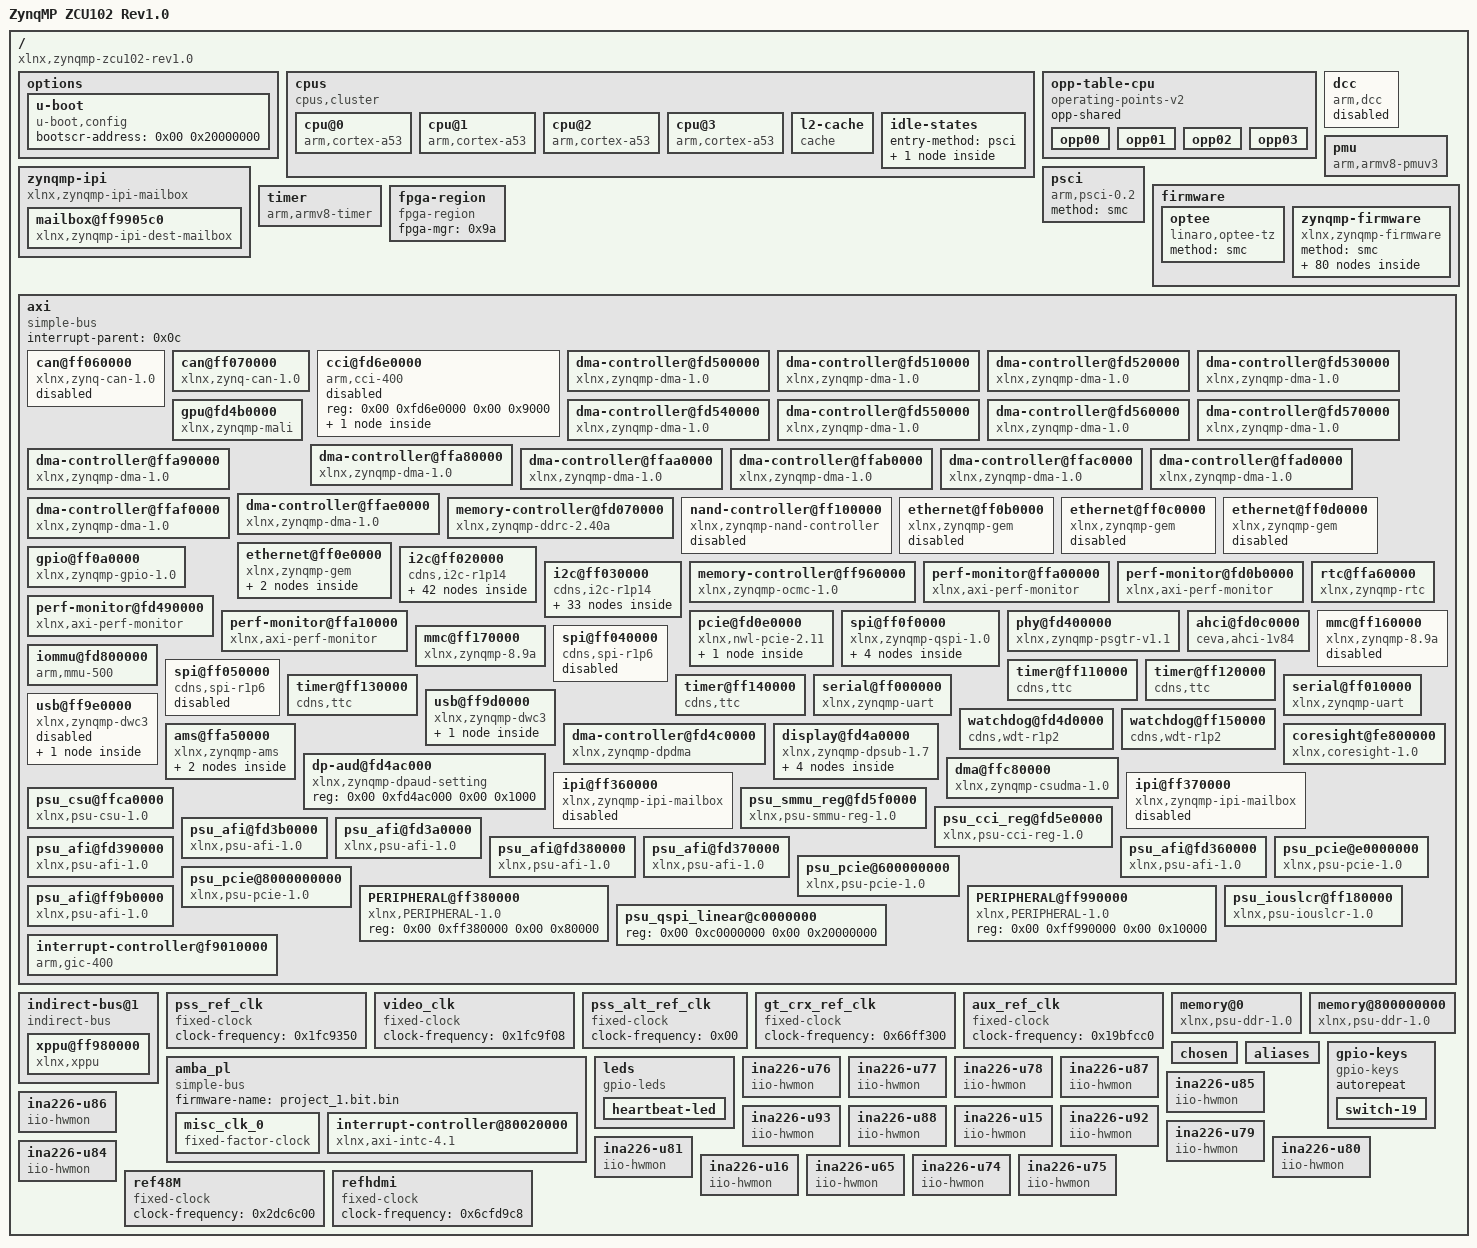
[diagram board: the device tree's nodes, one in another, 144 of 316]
/dts-v1/;

/ {
	compatible = "xlnx,zynqmp-zcu102-rev1.0\0xlnx,zynqmp-zcu102\0xlnx,zynqmp";
	#address-cells = <0x02>;
	#size-cells = <0x02>;
	model = "ZynqMP ZCU102 Rev1.0";
	board = "zcu102";
	device_id = "xczu9eg";
	slrcount = <0x01>;
	family = "ZynqMP";

	options {

		u-boot {
			compatible = "u-boot,config";
			bootscr-address = <0x00 0x20000000>;
		};
	};

	cpus {
		#address-cells = <0x01>;
		#size-cells = <0x00>;
		compatible = "cpus,cluster";
		#ranges-address-cells = <0x02>;
		#ranges-size-cells = <0x02>;
		phandle = <0xc4>;

		cpu@0 {
			compatible = "arm,cortex-a53";
			device_type = "cpu";
			enable-method = "psci";
			operating-points-v2 = <0x78>;
			reg = <0x00>;
			cpu-idle-states = <0x79>;
			next-level-cache = <0x7a>;
			clocks = <0x7b 0x0a>;
			xlnx,psu-ep = <0x01>;
			xlnx,pss-video-ref-clk-freq = <0x1fc9f08>;
			xlnx,ip-name = "psu_cortexa53";
			xlnx,cpu-1x-clk-freq-hz = <0x00>;
			xlnx,psu-silicon-version = <0x03>;
			cpu-frequency = <0x4784b7bf>;
			xlnx,cpu-clk-freq-hz = <0x4784b7bf>;
			xlnx,pss-gt-ref-clk-freq = <0x1fc9f08>;
			xlnx,pss-ref-clk-freq = <0x1fc9350>;
			bus-handle = <0x01>;
			xlnx,pss-aux-ref-clk-freq = <0x1fc9f08>;
			xlnx,psu-device = "PS8a";
			xlnx,timestamp-clk-freq = <0x5f5b9f5>;
			stamp-frequency = <0x5f5b9f5>;
			xlnx,pss-alt-ref-clk-freq = <0x1fc9f08>;
			phandle = <0x90>;
		};

		cpu@1 {
			compatible = "arm,cortex-a53";
			device_type = "cpu";
			enable-method = "psci";
			reg = <0x01>;
			operating-points-v2 = <0x78>;
			cpu-idle-states = <0x79>;
			next-level-cache = <0x7a>;
			xlnx,psu-ep = <0x01>;
			xlnx,ip-name = "psu_cortexa53";
			xlnx,cpu-1x-clk-freq-hz = <0x00>;
			cpu-frequency = <0x4784b7bf>;
			xlnx,cpu-clk-freq-hz = <0x4784b7bf>;
			xlnx,psu-silicon-version = <0x03>;
			xlnx,pss-ref-clk-freq = <0x1fc9350>;
			bus-handle = <0x01>;
			xlnx,psu-device = "PS8a";
			stamp-frequency = <0x5f5b9f5>;
			xlnx,timestamp-clk-freq = <0x5f5b9f5>;
			phandle = <0x91>;
		};

		cpu@2 {
			compatible = "arm,cortex-a53";
			device_type = "cpu";
			enable-method = "psci";
			reg = <0x02>;
			operating-points-v2 = <0x78>;
			cpu-idle-states = <0x79>;
			next-level-cache = <0x7a>;
			xlnx,psu-ep = <0x01>;
			xlnx,ip-name = "psu_cortexa53";
			xlnx,cpu-1x-clk-freq-hz = <0x00>;
			cpu-frequency = <0x4784b7bf>;
			xlnx,cpu-clk-freq-hz = <0x4784b7bf>;
			xlnx,psu-silicon-version = <0x03>;
			xlnx,pss-ref-clk-freq = <0x1fc9350>;
			bus-handle = <0x01>;
			xlnx,psu-device = "PS8a";
			stamp-frequency = <0x5f5b9f5>;
			xlnx,timestamp-clk-freq = <0x5f5b9f5>;
			phandle = <0x92>;
		};

		cpu@3 {
			compatible = "arm,cortex-a53";
			device_type = "cpu";
			enable-method = "psci";
			reg = <0x03>;
			operating-points-v2 = <0x78>;
			cpu-idle-states = <0x79>;
			next-level-cache = <0x7a>;
			xlnx,psu-ep = <0x01>;
			xlnx,ip-name = "psu_cortexa53";
			xlnx,cpu-1x-clk-freq-hz = <0x00>;
			cpu-frequency = <0x4784b7bf>;
			xlnx,cpu-clk-freq-hz = <0x4784b7bf>;
			xlnx,psu-silicon-version = <0x03>;
			xlnx,pss-ref-clk-freq = <0x1fc9350>;
			bus-handle = <0x01>;
			xlnx,psu-device = "PS8a";
			stamp-frequency = <0x5f5b9f5>;
			xlnx,timestamp-clk-freq = <0x5f5b9f5>;
			phandle = <0x93>;
		};

		l2-cache {
			compatible = "cache";
			cache-level = <0x02>;
			cache-unified;
			phandle = <0x7a>;
		};

		idle-states {
			entry-method = "psci";

			cpu-sleep-0 {
				compatible = "arm,idle-state";
				arm,psci-suspend-param = <0x40000000>;
				local-timer-stop;
				entry-latency-us = <0x12c>;
				exit-latency-us = <0x258>;
				min-residency-us = <0x2710>;
				phandle = <0x79>;
			};
		};
	};

	opp-table-cpu {
		compatible = "operating-points-v2";
		opp-shared;
		phandle = <0x78>;

		opp00 {
			opp-hz = <0x00 0x47868bf4>;
			opp-microvolt = <0xf4240>;
			clock-latency-ns = <0x7a120>;
		};

		opp01 {
			opp-hz = <0x00 0x23c345fa>;
			opp-microvolt = <0xf4240>;
			clock-latency-ns = <0x7a120>;
		};

		opp02 {
			opp-hz = <0x00 0x17d783fc>;
			opp-microvolt = <0xf4240>;
			clock-latency-ns = <0x7a120>;
		};

		opp03 {
			opp-hz = <0x00 0x11e1a2fd>;
			opp-microvolt = <0xf4240>;
			clock-latency-ns = <0x7a120>;
		};
	};

	zynqmp-ipi {
		bootph-all;
		compatible = "xlnx,zynqmp-ipi-mailbox";
		interrupt-parent = <0x0c>;
		interrupts = <0x00 0x23 0x04>;
		xlnx,ipi-id = <0x00>;
		#address-cells = <0x02>;
		#size-cells = <0x02>;
		ranges;
		phandle = <0xcb>;

		mailbox@ff9905c0 {
			bootph-all;
			compatible = "xlnx,zynqmp-ipi-dest-mailbox";
			reg = <0x00 0xff9905c0 0x00 0x20 0x00 0xff9905e0 0x00 0x20 0x00 0xff990e80 0x00 0x20 0x00 0xff990ea0 0x00 0x20>;
			reg-names = "local_request_region\0local_response_region\0remote_request_region\0remote_response_region";
			#mbox-cells = <0x01>;
			xlnx,ipi-id = <0x04>;
			phandle = <0x94>;
		};
	};

	dcc {
		compatible = "arm,dcc";
		status = "disabled";
		bootph-all;
		phandle = <0xcc>;
	};

	pmu {
		compatible = "arm,armv8-pmuv3";
		interrupt-parent = <0x0c>;
		interrupts = <0x00 0x8f 0x04 0x00 0x90 0x04 0x00 0x91 0x04 0x00 0x92 0x04>;
		interrupt-affinity = <0x90 0x91 0x92 0x93>;
	};

	psci {
		compatible = "arm,psci-0.2";
		method = "smc";
	};

	firmware {

		optee {
			compatible = "linaro,optee-tz";
			method = "smc";
			phandle = <0xcd>;
		};

		zynqmp-firmware {
			compatible = "xlnx,zynqmp-firmware";
			#power-domain-cells = <0x01>;
			method = "smc";
			bootph-all;
			phandle = <0x84>;

			power-management {
				bootph-all;
				compatible = "xlnx,zynqmp-power";
				interrupt-parent = <0x0c>;
				interrupts = <0x00 0x23 0x04>;
				mboxes = <0x94 0x00 0x94 0x01>;
				mbox-names = "tx\0rx";
				phandle = <0xce>;
			};

			soc-nvmem {
				compatible = "xlnx,zynqmp-nvmem-fw";

				nvmem-layout {
					compatible = "fixed-layout";
					#address-cells = <0x01>;
					#size-cells = <0x01>;

					soc-revision@0 {
						reg = <0x00 0x04>;
						phandle = <0xcf>;
					};

					efuse-dna@c {
						reg = <0x0c 0x0c>;
						phandle = <0xd0>;
					};

					efuse-usr0@20 {
						reg = <0x20 0x04>;
						phandle = <0xd1>;
					};

					efuse-usr1@24 {
						reg = <0x24 0x04>;
						phandle = <0xd2>;
					};

					efuse-usr2@28 {
						reg = <0x28 0x04>;
						phandle = <0xd3>;
					};

					efuse-usr3@2c {
						reg = <0x2c 0x04>;
						phandle = <0xd4>;
					};

					efuse-usr4@30 {
						reg = <0x30 0x04>;
						phandle = <0xd5>;
					};

					efuse-usr5@34 {
						reg = <0x34 0x04>;
						phandle = <0xd6>;
					};

					efuse-usr6@38 {
						reg = <0x38 0x04>;
						phandle = <0xd7>;
					};

					efuse-usr7@3c {
						reg = <0x3c 0x04>;
						phandle = <0xd8>;
					};

					efuse-miscusr@40 {
						reg = <0x40 0x04>;
						phandle = <0xd9>;
					};

					efuse-chash@50 {
						reg = <0x50 0x04>;
						phandle = <0xda>;
					};

					efuse-pufmisc@54 {
						reg = <0x54 0x04>;
						phandle = <0xdb>;
					};

					efuse-sec@58 {
						reg = <0x58 0x04>;
						phandle = <0xdc>;
					};

					efuse-spkid@5c {
						reg = <0x5c 0x04>;
						phandle = <0xdd>;
					};

					efuse-aeskey@60 {
						reg = <0x60 0x20>;
						phandle = <0xde>;
					};

					efuse-ppk0hash@a0 {
						reg = <0xa0 0x30>;
						phandle = <0xdf>;
					};

					efuse-ppk1hash@d0 {
						reg = <0xd0 0x30>;
						phandle = <0xe0>;
					};

					efuse-pufuser@100 {
						reg = <0x100 0x7f>;
						phandle = <0xe1>;
					};
				};
			};

			pcap {
				compatible = "xlnx,zynqmp-pcap-fpga";
				phandle = <0x9a>;
			};

			reset-controller {
				compatible = "xlnx,zynqmp-reset";
				#reset-cells = <0x01>;
				status = "okay";
				phandle = <0x03>;
			};

			pinctrl {
				compatible = "xlnx,zynqmp-pinctrl";
				status = "okay";
				phandle = <0x04>;

				i2c0-default {
					phandle = <0xa0>;

					mux {
						groups = "i2c0_3_grp";
						function = "i2c0";
					};

					conf {
						groups = "i2c0_3_grp";
						bias-pull-up;
						slew-rate = <0x01>;
						power-source = <0x01>;
					};
				};

				i2c0-gpio-grp {
					phandle = <0xa1>;

					mux {
						groups = "gpio0_14_grp\0gpio0_15_grp";
						function = "gpio0";
					};

					conf {
						groups = "gpio0_14_grp\0gpio0_15_grp";
						slew-rate = <0x01>;
						power-source = <0x01>;
					};
				};

				i2c1-default {
					phandle = <0xa2>;

					mux {
						groups = "i2c1_4_grp";
						function = "i2c1";
					};

					conf {
						groups = "i2c1_4_grp";
						bias-pull-up;
						slew-rate = <0x01>;
						power-source = <0x01>;
					};
				};

				i2c1-gpio-grp {
					phandle = <0xa3>;

					mux {
						groups = "gpio0_16_grp\0gpio0_17_grp";
						function = "gpio0";
					};

					conf {
						groups = "gpio0_16_grp\0gpio0_17_grp";
						slew-rate = <0x01>;
						power-source = <0x01>;
					};
				};

				uart0-default {
					phandle = <0xa9>;

					mux {
						groups = "uart0_4_grp";
						function = "uart0";
					};

					conf {
						groups = "uart0_4_grp";
						slew-rate = <0x01>;
						power-source = <0x01>;
					};

					conf-rx {
						pins = "MIO18";
						bias-high-impedance;
					};

					conf-tx {
						pins = "MIO19";
						bias-disable;
					};
				};

				uart1-default {
					phandle = <0xaa>;

					mux {
						groups = "uart1_5_grp";
						function = "uart1";
					};

					conf {
						groups = "uart1_5_grp";
						slew-rate = <0x01>;
						power-source = <0x01>;
					};

					conf-rx {
						pins = "MIO21";
						bias-high-impedance;
					};

					conf-tx {
						pins = "MIO20";
						bias-disable;
					};
				};

				usb0-default {
					phandle = <0xac>;

					mux {
						groups = "usb0_0_grp";
						function = "usb0";
					};

					conf {
						groups = "usb0_0_grp";
						power-source = <0x01>;
					};

					conf-rx {
						pins = "MIO52\0MIO53\0MIO55";
						bias-high-impedance;
						drive-strength = <0x0c>;
						slew-rate = <0x00>;
					};

					conf-tx {
						pins = "MIO54\0MIO56\0MIO57\0MIO58\0MIO59\0MIO60\0MIO61\0MIO62\0MIO63";
						bias-disable;
						drive-strength = <0x04>;
						slew-rate = <0x01>;
					};
				};

				gem3-default {
					phandle = <0x9d>;

					mux {
						function = "ethernet3";
						groups = "ethernet3_0_grp";
					};

					conf {
						groups = "ethernet3_0_grp";
						slew-rate = <0x01>;
						power-source = <0x01>;
					};

					conf-rx {
						pins = "MIO70\0MIO71\0MIO72\0MIO73\0MIO74\0MIO75";
						bias-high-impedance;
						low-power-disable;
					};

					conf-tx {
						pins = "MIO64\0MIO65\0MIO66\0MIO67\0MIO68\0MIO69";
						bias-disable;
						low-power-enable;
					};

					mux-mdio {
						function = "mdio3";
						groups = "mdio3_0_grp";
					};

					conf-mdio {
						groups = "mdio3_0_grp";
						slew-rate = <0x01>;
						power-source = <0x01>;
						bias-disable;
					};
				};

				can1-default {
					phandle = <0x9b>;

					mux {
						function = "can1";
						groups = "can1_6_grp";
					};

					conf {
						groups = "can1_6_grp";
						slew-rate = <0x01>;
						power-source = <0x01>;
					};

					conf-rx {
						pins = "MIO25";
						bias-high-impedance;
					};

					conf-tx {
						pins = "MIO24";
						bias-disable;
					};
				};

				sdhci1-default {
					phandle = <0xa8>;

					mux {
						groups = "sdio1_0_grp";
						function = "sdio1";
					};

					conf {
						groups = "sdio1_0_grp";
						slew-rate = <0x01>;
						power-source = <0x01>;
						bias-disable;
					};

					mux-cd {
						groups = "sdio1_cd_0_grp";
						function = "sdio1_cd";
					};

					conf-cd {
						groups = "sdio1_cd_0_grp";
						bias-high-impedance;
						bias-pull-up;
						slew-rate = <0x01>;
						power-source = <0x01>;
					};

					mux-wp {
						groups = "sdio1_wp_0_grp";
						function = "sdio1_wp";
					};

					conf-wp {
						groups = "sdio1_wp_0_grp";
						bias-high-impedance;
						bias-pull-up;
						slew-rate = <0x01>;
						power-source = <0x01>;
					};
				};

				gpio-default {
					phandle = <0x9f>;

					mux-sw {
						function = "gpio0";
						groups = "gpio0_22_grp\0gpio0_23_grp";
					};

					conf-sw {
						groups = "gpio0_22_grp\0gpio0_23_grp";
						slew-rate = <0x01>;
						power-source = <0x01>;
					};

					mux-msp {
						function = "gpio0";
						groups = "gpio0_13_grp\0gpio0_38_grp";
					};

					conf-msp {
						groups = "gpio0_13_grp\0gpio0_38_grp";
						slew-rate = <0x01>;
						power-source = <0x01>;
					};

					conf-pull-up {
						pins = "MIO22\0MIO23";
						bias-pull-up;
					};

					conf-pull-none {
						pins = "MIO13\0MIO38";
						bias-disable;
					};
				};
			};

			gpio {
				compatible = "xlnx,zynqmp-gpio-modepin";
				gpio-controller;
				#gpio-cells = <0x02>;
				phandle = <0xab>;
			};

			clock-controller {
				bootph-all;
				#clock-cells = <0x01>;
				compatible = "xlnx,zynqmp-clk";
				clocks = <0x95 0x96 0x97 0x98 0x99>;
				clock-names = "pss_ref_clk\0video_clk\0pss_alt_ref_clk\0aux_ref_clk\0gt_crx_ref_clk";
				phandle = <0x7b>;
			};
		};
	};

	timer {
		compatible = "arm,armv8-timer";
		interrupt-parent = <0x0c>;
		interrupts = <0x01 0x0d 0xf08 0x01 0x0e 0xf08 0x01 0x0b 0xf08 0x01 0x0a 0xf08>;
	};

	fpga-region {
		compatible = "fpga-region";
		fpga-mgr = <0x9a>;
		#address-cells = <0x02>;
		#size-cells = <0x02>;
		ranges;
		phandle = <0xe2>;
	};

	axi {
		compatible = "simple-bus";
		bootph-all;
		#address-cells = <0x02>;
		#size-cells = <0x02>;
		ranges;
		interrupt-parent = <0x0c>;
		phandle = <0x01>;

		can@ff060000 {
			compatible = "xlnx,zynq-can-1.0";
			status = "disabled";
			clock-names = "can_clk\0pclk";
			reg = <0x00 0xff060000 0x00 0x1000>;
			interrupts = <0x00 0x17 0x04>;
			interrupt-parent = <0x0c>;
			tx-fifo-depth = <0x40>;
			rx-fifo-depth = <0x40>;
			resets = <0x03 0x28>;
			power-domains = <0x84 0x2f>;
			clocks = <0x7b 0x3f 0x7b 0x1f>;
			phandle = <0xe3>;
		};

		can@ff070000 {
			compatible = "xlnx,zynq-can-1.0";
			status = "okay";
			clock-names = "can_clk\0pclk";
			reg = <0x00 0xff070000 0x00 0x1000>;
			interrupts = <0x00 0x18 0x04>;
			interrupt-parent = <0x0c>;
			tx-fifo-depth = <0x40>;
			rx-fifo-depth = <0x40>;
			resets = <0x03 0x29>;
			power-domains = <0x84 0x30>;
			clocks = <0x7b 0x40 0x7b 0x1f>;
			xlnx,can-clk-freq-hz = <0x5f5b9f5>;
			xlnx,ip-name = "psu_can";
			xlnx,can-board-interface = "custom";
			pinctrl-names = "default";
			pinctrl-0 = <0x9b>;
			phandle = <0x22>;
		};

		cci@fd6e0000 {
			compatible = "arm,cci-400";
			status = "disabled";
			reg = <0x00 0xfd6e0000 0x00 0x9000>;
			ranges = <0x00 0x00 0xfd6e0000 0x10000>;
			#address-cells = <0x01>;
			#size-cells = <0x01>;
			phandle = <0xe4>;

			pmu@9000 {
				compatible = "arm,cci-400-pmu,r1";
				reg = <0x9000 0x5000>;
				interrupt-parent = <0x0c>;
				interrupts = <0x00 0x7b 0x04 0x00 0x7b 0x04 0x00 0x7b 0x04 0x00 0x7b 0x04 0x00 0x7b 0x04>;
			};
		};

		dma-controller@fd500000 {
			status = "okay";
			compatible = "xlnx,zynqmp-dma-1.0";
			reg = <0x00 0xfd500000 0x00 0x1000>;
			interrupt-parent = <0x0c>;
			interrupts = <0x00 0x7c 0x04>;
			clock-names = "clk_main\0clk_apb";
			#dma-cells = <0x01>;
			xlnx,bus-width = <0x80>;
			power-domains = <0x84 0x2a>;
			clocks = <0x7b 0x13 0x7b 0x1f>;
			xlnx,ip-name = "psu_gdma";
			xlnx,dma-mode = <0x00>;
			xlnx,dma-type = <0x00>;
			phandle = <0x3d>;
		};

		dma-controller@fd510000 {
			status = "okay";
			compatible = "xlnx,zynqmp-dma-1.0";
			reg = <0x00 0xfd510000 0x00 0x1000>;
			interrupt-parent = <0x0c>;
			interrupts = <0x00 0x7d 0x04>;
			clock-names = "clk_main\0clk_apb";
			#dma-cells = <0x01>;
			xlnx,bus-width = <0x80>;
			power-domains = <0x84 0x2a>;
			clocks = <0x7b 0x13 0x7b 0x1f>;
			xlnx,ip-name = "psu_gdma";
			xlnx,dma-mode = <0x00>;
			xlnx,dma-type = <0x00>;
			phandle = <0x3e>;
		};

		dma-controller@fd520000 {
			status = "okay";
			compatible = "xlnx,zynqmp-dma-1.0";
			reg = <0x00 0xfd520000 0x00 0x1000>;
			interrupt-parent = <0x0c>;
			interrupts = <0x00 0x7e 0x04>;
			clock-names = "clk_main\0clk_apb";
			#dma-cells = <0x01>;
			xlnx,bus-width = <0x80>;
			power-domains = <0x84 0x2a>;
			clocks = <0x7b 0x13 0x7b 0x1f>;
			xlnx,ip-name = "psu_gdma";
			xlnx,dma-mode = <0x00>;
			xlnx,dma-type = <0x00>;
			phandle = <0x3f>;
		};

		dma-controller@fd530000 {
			status = "okay";
			compatible = "xlnx,zynqmp-dma-1.0";
			reg = <0x00 0xfd530000 0x00 0x1000>;
			interrupt-parent = <0x0c>;
			interrupts = <0x00 0x7f 0x04>;
			clock-names = "clk_main\0clk_apb";
			#dma-cells = <0x01>;
			xlnx,bus-width = <0x80>;
			power-domains = <0x84 0x2a>;
			clocks = <0x7b 0x13 0x7b 0x1f>;
			xlnx,ip-name = "psu_gdma";
			xlnx,dma-mode = <0x00>;
			xlnx,dma-type = <0x00>;
			phandle = <0x40>;
		};

		dma-controller@fd540000 {
			status = "okay";
			compatible = "xlnx,zynqmp-dma-1.0";
			reg = <0x00 0xfd540000 0x00 0x1000>;
			interrupt-parent = <0x0c>;
			interrupts = <0x00 0x80 0x04>;
			clock-names = "clk_main\0clk_apb";
			#dma-cells = <0x01>;
			xlnx,bus-width = <0x80>;
			power-domains = <0x84 0x2a>;
			clocks = <0x7b 0x13 0x7b 0x1f>;
			xlnx,ip-name = "psu_gdma";
			xlnx,dma-mode = <0x00>;
			xlnx,dma-type = <0x00>;
			phandle = <0x41>;
		};

		dma-controller@fd550000 {
			status = "okay";
			compatible = "xlnx,zynqmp-dma-1.0";
			reg = <0x00 0xfd550000 0x00 0x1000>;
			interrupt-parent = <0x0c>;
			interrupts = <0x00 0x81 0x04>;
			clock-names = "clk_main\0clk_apb";
			#dma-cells = <0x01>;
			xlnx,bus-width = <0x80>;
			power-domains = <0x84 0x2a>;
			clocks = <0x7b 0x13 0x7b 0x1f>;
			xlnx,ip-name = "psu_gdma";
			xlnx,dma-mode = <0x00>;
			xlnx,dma-type = <0x00>;
			phandle = <0x42>;
		};

		dma-controller@fd560000 {
			status = "okay";
			compatible = "xlnx,zynqmp-dma-1.0";
			reg = <0x00 0xfd560000 0x00 0x1000>;
			interrupt-parent = <0x0c>;
			interrupts = <0x00 0x82 0x04>;
			clock-names = "clk_main\0clk_apb";
			#dma-cells = <0x01>;
			xlnx,bus-width = <0x80>;
			power-domains = <0x84 0x2a>;
			clocks = <0x7b 0x13 0x7b 0x1f>;
			xlnx,ip-name = "psu_gdma";
			xlnx,dma-mode = <0x00>;
			xlnx,dma-type = <0x00>;
			phandle = <0x43>;
		};

		dma-controller@fd570000 {
			status = "okay";
			compatible = "xlnx,zynqmp-dma-1.0";
			reg = <0x00 0xfd570000 0x00 0x1000>;
			interrupt-parent = <0x0c>;
			interrupts = <0x00 0x83 0x04>;
			clock-names = "clk_main\0clk_apb";
			#dma-cells = <0x01>;
			xlnx,bus-width = <0x80>;
			power-domains = <0x84 0x2a>;
			clocks = <0x7b 0x13 0x7b 0x1f>;
			xlnx,ip-name = "psu_gdma";
			xlnx,dma-mode = <0x00>;
			xlnx,dma-type = <0x00>;
			phandle = <0x44>;
		};

		gpu@fd4b0000 {
			status = "okay";
			compatible = "xlnx,zynqmp-mali\0arm,mali-400";
			reg = <0x00 0xfd4b0000 0x00 0x10000>;
			interrupt-parent = <0x0c>;
			interrupts = <0x00 0x84 0x04 0x00 0x84 0x04 0x00 0x84 0x04 0x00 0x84 0x04 0x00 0x84 0x04 0x00 0x84 0x04>;
			interrupt-names = "gp\0gpmmu\0pp0\0ppmmu0\0pp1\0ppmmu1";
			clock-names = "bus\0core";
			power-domains = <0x84 0x3a>;
			clocks = <0x7b 0x18 0x7b 0x19>;
			xlnx,ip-name = "psu_gpu";
			xlnx,tz-nonsecure = <0x01>;
			phandle = <0x46>;
		};

		dma-controller@ffa80000 {
			status = "okay";
			compatible = "xlnx,zynqmp-dma-1.0";
			reg = <0x00 0xffa80000 0x00 0x1000>;
			interrupt-parent = <0x0c>;
			interrupts = <0x00 0x4d 0x04>;
			clock-names = "clk_main\0clk_apb";
			#dma-cells = <0x01>;
			xlnx,bus-width = <0x40>;
			power-domains = <0x84 0x2b>;
			clocks = <0x7b 0x44 0x7b 0x1f>;
			xlnx,is-cache-coherent = <0x00>;
			xlnx,ip-name = "psu_adma";
			xlnx,dma-mode = <0x01>;
			xlnx,dma-type = <0x01>;
			phandle = <0x0d>;
		};

		dma-controller@ffa90000 {
			status = "okay";
			compatible = "xlnx,zynqmp-dma-1.0";
			reg = <0x00 0xffa90000 0x00 0x1000>;
			interrupt-parent = <0x0c>;
			interrupts = <0x00 0x4e 0x04>;
			clock-names = "clk_main\0clk_apb";
			#dma-cells = <0x01>;
			xlnx,bus-width = <0x40>;
			power-domains = <0x84 0x2b>;
			clocks = <0x7b 0x44 0x7b 0x1f>;
			xlnx,is-cache-coherent = <0x00>;
			xlnx,ip-name = "psu_adma";
			xlnx,dma-mode = <0x01>;
			xlnx,dma-type = <0x01>;
			phandle = <0x0e>;
		};

		dma-controller@ffaa0000 {
			status = "okay";
			compatible = "xlnx,zynqmp-dma-1.0";
			reg = <0x00 0xffaa0000 0x00 0x1000>;
			interrupt-parent = <0x0c>;
			interrupts = <0x00 0x4f 0x04>;
			clock-names = "clk_main\0clk_apb";
			#dma-cells = <0x01>;
			xlnx,bus-width = <0x40>;
			power-domains = <0x84 0x2b>;
			clocks = <0x7b 0x44 0x7b 0x1f>;
			xlnx,is-cache-coherent = <0x00>;
			xlnx,ip-name = "psu_adma";
			xlnx,dma-mode = <0x01>;
			xlnx,dma-type = <0x01>;
			phandle = <0x0f>;
		};

		dma-controller@ffab0000 {
			status = "okay";
			compatible = "xlnx,zynqmp-dma-1.0";
			reg = <0x00 0xffab0000 0x00 0x1000>;
			interrupt-parent = <0x0c>;
			interrupts = <0x00 0x50 0x04>;
			clock-names = "clk_main\0clk_apb";
			#dma-cells = <0x01>;
			xlnx,bus-width = <0x40>;
			power-domains = <0x84 0x2b>;
			clocks = <0x7b 0x44 0x7b 0x1f>;
			xlnx,is-cache-coherent = <0x00>;
			xlnx,ip-name = "psu_adma";
			xlnx,dma-mode = <0x01>;
			xlnx,dma-type = <0x01>;
			phandle = <0x10>;
		};

		dma-controller@ffac0000 {
			status = "okay";
			compatible = "xlnx,zynqmp-dma-1.0";
			reg = <0x00 0xffac0000 0x00 0x1000>;
			interrupt-parent = <0x0c>;
			interrupts = <0x00 0x51 0x04>;
			clock-names = "clk_main\0clk_apb";
			#dma-cells = <0x01>;
			xlnx,bus-width = <0x40>;
			power-domains = <0x84 0x2b>;
			clocks = <0x7b 0x44 0x7b 0x1f>;
			xlnx,is-cache-coherent = <0x00>;
			xlnx,ip-name = "psu_adma";
			xlnx,dma-mode = <0x01>;
			xlnx,dma-type = <0x01>;
			phandle = <0x11>;
		};

		dma-controller@ffad0000 {
			status = "okay";
			compatible = "xlnx,zynqmp-dma-1.0";
			reg = <0x00 0xffad0000 0x00 0x1000>;
			interrupt-parent = <0x0c>;
			interrupts = <0x00 0x52 0x04>;
			clock-names = "clk_main\0clk_apb";
			#dma-cells = <0x01>;
			xlnx,bus-width = <0x40>;
			power-domains = <0x84 0x2b>;
			clocks = <0x7b 0x44 0x7b 0x1f>;
			xlnx,is-cache-coherent = <0x00>;
			xlnx,ip-name = "psu_adma";
			xlnx,dma-mode = <0x01>;
			xlnx,dma-type = <0x01>;
			phandle = <0x12>;
		};

		dma-controller@ffae0000 {
			status = "okay";
			compatible = "xlnx,zynqmp-dma-1.0";
			reg = <0x00 0xffae0000 0x00 0x1000>;
			interrupt-parent = <0x0c>;
			interrupts = <0x00 0x53 0x04>;
			clock-names = "clk_main\0clk_apb";
			#dma-cells = <0x01>;
			xlnx,bus-width = <0x40>;
			power-domains = <0x84 0x2b>;
			clocks = <0x7b 0x44 0x7b 0x1f>;
			xlnx,is-cache-coherent = <0x00>;
			xlnx,ip-name = "psu_adma";
			xlnx,dma-mode = <0x01>;
			xlnx,dma-type = <0x01>;
			phandle = <0x13>;
		};

		dma-controller@ffaf0000 {
			status = "okay";
			compatible = "xlnx,zynqmp-dma-1.0";
			reg = <0x00 0xffaf0000 0x00 0x1000>;
			interrupt-parent = <0x0c>;
			interrupts = <0x00 0x54 0x04>;
			clock-names = "clk_main\0clk_apb";
			#dma-cells = <0x01>;
			xlnx,bus-width = <0x40>;
			power-domains = <0x84 0x2b>;
			clocks = <0x7b 0x44 0x7b 0x1f>;
			xlnx,is-cache-coherent = <0x00>;
			xlnx,ip-name = "psu_adma";
			xlnx,dma-mode = <0x01>;
			xlnx,dma-type = <0x01>;
			phandle = <0x14>;
		};

		memory-controller@fd070000 {
			compatible = "xlnx,zynqmp-ddrc-2.40a";
			reg = <0x00 0xfd070000 0x00 0x30000>;
			interrupt-parent = <0x0c>;
			interrupts = <0x00 0x70 0x04>;
			xlnx,bank-addr-bits = <0x02>;
			xlnx,ddrc-parity = <0x00>;
			xlnx,addr-mapping = <0x00>;
			xlnx,has-ecc = <0x00>;
			xlnx,ddr-freq = <0x3f926a3a>;
			xlnx,row-addr-bits = <0x0f>;
			xlnx,ddrc-low-power-auto-self-refresh = <0x00>;
			xlnx,ip-name = "psu_ddrc";
			xlnx,ddrc-2nd-clock = <0x00>;
			xlnx,brc-mapping = <0x00>;
			xlnx,ddrc-address-copy = <0x00>;
			xlnx,ddrc-data-mask-and-dbi = <0x07>;
			xlnx,ddrc-fine-granularity-refresh-mode = <0x00>;
			xlnx,ddrc-memory-type = <0x04>;
			xlnx,col-addr-bits = <0x0a>;
			xlnx,ddrc-self-refresh-abort = <0x00>;
			xlnx,ddrc-max-operating-temparature = <0x00>;
			status = "okay";
			xlnx,ddrc-address-mirroring = <0x00>;
			xlnx,ddrc-clk-freq-hz = <0x1fc9351d>;
			xlnx,qos-enable = <0x00>;
			xlnx,ddrc-temp-controlled-refresh = <0x00>;
			xlnx,bg-addr-bits = <0x02>;
			xlnx,ddrc-power-down-enable = <0x00>;
			xlnx,video-buf-size = <0x00>;
			xlnx,ddrc-memory-address-map = <0x00>;
			xlnx,dddrc-ecc = <0x00>;
			xlnx,ddrc-clock-stop = <0x00>;
			xlnx,ddrc-dynamic-ddr-config-enabled = <0x01>;
			phandle = <0x33>;
		};

		nand-controller@ff100000 {
			compatible = "xlnx,zynqmp-nand-controller\0arasan,nfc-v3p10";
			status = "disabled";
			reg = <0x00 0xff100000 0x00 0x1000>;
			clock-names = "controller\0bus";
			interrupt-parent = <0x0c>;
			interrupts = <0x00 0x0e 0x04>;
			#address-cells = <0x01>;
			#size-cells = <0x00>;
			power-domains = <0x84 0x2c>;
			clocks = <0x7b 0x3c 0x7b 0x1f>;
			phandle = <0xe5>;
		};

		ethernet@ff0b0000 {
			compatible = "xlnx,zynqmp-gem\0cdns,gem";
			status = "disabled";
			interrupt-parent = <0x0c>;
			interrupts = <0x00 0x39 0x04 0x00 0x39 0x04>;
			reg = <0x00 0xff0b0000 0x00 0x1000>;
			clock-names = "pclk\0hclk\0tx_clk\0rx_clk\0tsu_clk";
			power-domains = <0x84 0x1d>;
			resets = <0x03 0x1d>;
			reset-names = "gem0_rst";
			clocks = <0x7b 0x1f 0x7b 0x68 0x7b 0x2d 0x7b 0x31 0x7b 0x2c>;
			assigned-clocks = <0x7b 0x2c>;
			phandle = <0xe6>;
		};

		ethernet@ff0c0000 {
			compatible = "xlnx,zynqmp-gem\0cdns,gem";
			status = "disabled";
			interrupt-parent = <0x0c>;
			interrupts = <0x00 0x3b 0x04 0x00 0x3b 0x04>;
			reg = <0x00 0xff0c0000 0x00 0x1000>;
			clock-names = "pclk\0hclk\0tx_clk\0rx_clk\0tsu_clk";
			power-domains = <0x84 0x1e>;
			resets = <0x03 0x1e>;
			reset-names = "gem1_rst";
			clocks = <0x7b 0x1f 0x7b 0x69 0x7b 0x2e 0x7b 0x32 0x7b 0x2c>;
			assigned-clocks = <0x7b 0x2c>;
			phandle = <0xe7>;
		};

		ethernet@ff0d0000 {
			compatible = "xlnx,zynqmp-gem\0cdns,gem";
			status = "disabled";
			interrupt-parent = <0x0c>;
			interrupts = <0x00 0x3d 0x04 0x00 0x3d 0x04>;
			reg = <0x00 0xff0d0000 0x00 0x1000>;
			clock-names = "pclk\0hclk\0tx_clk\0rx_clk\0tsu_clk";
			power-domains = <0x84 0x1f>;
			resets = <0x03 0x1f>;
			reset-names = "gem2_rst";
			clocks = <0x7b 0x1f 0x7b 0x6a 0x7b 0x2f 0x7b 0x33 0x7b 0x2c>;
			assigned-clocks = <0x7b 0x2c>;
			phandle = <0xe8>;
		};

		ethernet@ff0e0000 {
			compatible = "xlnx,zynqmp-gem\0cdns,gem";
			status = "okay";
			interrupt-parent = <0x0c>;
			interrupts = <0x00 0x3f 0x04 0x00 0x3f 0x04>;
			reg = <0x00 0xff0e0000 0x00 0x1000>;
			clock-names = "pclk\0hclk\0tx_clk\0rx_clk\0tsu_clk";
			power-domains = <0x84 0x20>;
			resets = <0x03 0x20>;
			reset-names = "gem3_rst";
			clocks = <0x7b 0x1f 0x7b 0x6b 0x7b 0x30 0x7b 0x34 0x7b 0x2c>;
			assigned-clocks = <0x7b 0x2c>;
			xlnx,is-cache-coherent = <0x00>;
			xlnx,has-mdio = <0x2faf080>;
			xlnx,gem-board-interface = "custom";
			phy-mode = "rgmii-id";
			xlnx,tz-nonsecure = <0x01>;
			xlnx,enet-slcr-1000mbps-div0 = <0x0c>;
			xlnx,enet-slcr-10mbps-div0 = <0x3c>;
			xlnx,enet-slcr-1000mbps-div1 = <0x01>;
			xlnx,enet-slcr-10mbps-div1 = <0x0a>;
			xlnx,enet-tsu-clk-freq-hz = <0xee650ed>;
			xlnx,ip-name = "psu_ethernet";
			xlnx,eth-mode = <0x01>;
			xlnx,enet-reset = <0x2faf080>;
			xlnx,enet-clk-freq-hz = <0x7732877>;
			xlnx,enet-slcr-100mbps-div0 = <0x3c>;
			xlnx,ptp-enet-clock = <0x00>;
			local-mac-address = [ff ff ff ff ff ff];
			xlnx,enet-slcr-100mbps-div1 = <0x01>;
			phy-handle = <0x9c>;
			pinctrl-names = "default";
			pinctrl-0 = <0x9d>;
			phandle = <0x37>;

			mdio {
				#address-cells = <0x01>;
				#size-cells = <0x00>;
				phandle = <0xe9>;

				ethernet-phy@c {
					#phy-cells = <0x01>;
					compatible = "ethernet-phy-id2000.a231";
					reg = <0x0c>;
					ti,rx-internal-delay = <0x08>;
					ti,tx-internal-delay = <0x0a>;
					ti,fifo-depth = <0x01>;
					ti,dp83867-rxctrl-strap-quirk;
					reset-gpios = <0x9e 0x06 0x01>;
					phandle = <0x9c>;
				};
			};
		};

		gpio@ff0a0000 {
			compatible = "xlnx,zynqmp-gpio-1.0";
			status = "okay";
			#gpio-cells = <0x02>;
			gpio-controller;
			interrupt-parent = <0x0c>;
			interrupts = <0x00 0x10 0x04>;
			interrupt-controller;
			#interrupt-cells = <0x02>;
			reg = <0x00 0xff0a0000 0x00 0x1000>;
			power-domains = <0x84 0x2e>;
			clocks = <0x7b 0x1f>;
			xlnx,gpio-board-interface = "custom";
			xlnx,mio-gpio-mask = <0x5600>;
			gpio-mask-high = <0x00>;
			xlnx,emio-gpio-width = <0x20>;
			xlnx,ip-name = "psu_gpio";
			gpio-mask-low = <0x5600>;
			emio-gpio-width = <0x20>;
			pinctrl-names = "default";
			pinctrl-0 = <0x9f>;
			phandle = <0x45>;
		};

		i2c@ff020000 {
			compatible = "cdns,i2c-r1p14";
			status = "okay";
			interrupt-parent = <0x0c>;
			interrupts = <0x00 0x11 0x04>;
			clock-frequency = <0x61a80>;
			reg = <0x00 0xff020000 0x00 0x1000>;
			#address-cells = <0x01>;
			#size-cells = <0x00>;
			power-domains = <0x84 0x25>;
			clocks = <0x7b 0x3d>;
			xlnx,i2c-reset = <0x00>;
			xlnx,has-interrupt = <0x2faf080>;
			xlnx,clock-freq = <0x5f5b9f5>;
			xlnx,i2c-clk-freq-hz = <0x5f5b9f5>;
			xlnx,ip-name = "psu_i2c";
			xlnx,iic-board-interface = "custom";
			pinctrl-names = "default\0gpio";
			pinctrl-0 = <0xa0>;
			pinctrl-1 = <0xa1>;
			scl-gpios = <0x45 0x0e 0x06>;
			sda-gpios = <0x45 0x0f 0x06>;
			phandle = <0x47>;

			gpio@20 {
				compatible = "ti,tca6416";
				reg = <0x20>;
				gpio-controller;
				#gpio-cells = <0x02>;
				gpio-line-names = "PS_GTR_LAN_SEL0\0PS_GTR_LAN_SEL1\0PS_GTR_LAN_SEL2\0PS_GTR_LAN_SEL3\0PCI_CLK_DIR_SEL\0IIC_MUX_RESET_B\0GEM3_EXP_RESET_B\0\0\0\0\0\0\0\0\0";
				phandle = <0x9e>;

				gtr-sel0-hog {
					gpio-hog;
					gpios = <0x00 0x00>;
					output-low;
					line-name = "sel0";
				};

				gtr-sel1-hog {
					gpio-hog;
					gpios = <0x01 0x00>;
					output-high;
					line-name = "sel1";
				};

				gtr-sel2-hog {
					gpio-hog;
					gpios = <0x02 0x00>;
					output-high;
					line-name = "sel2";
				};

				gtr-sel3-hog {
					gpio-hog;
					gpios = <0x03 0x00>;
					output-high;
					line-name = "sel3";
				};
			};

			gpio@21 {
				compatible = "ti,tca6416";
				reg = <0x21>;
				gpio-controller;
				#gpio-cells = <0x02>;
				gpio-line-names = "VCCPSPLL_EN\0MGTRAVCC_EN\0MGTRAVTT_EN\0VCCPSDDRPLL_EN\0MIO26_PMU_INPUT_LS\0PL_PMBUS_ALERT\0PS_PMBUS_ALERT\0MAXIM_PMBUS_ALERT\0PL_DDR4_VTERM_EN\0PL_DDR4_VPP_2V5_EN\0PS_DIMM_VDDQ_TO_PSVCCO_ON\0PS_DIMM_SUSPEND_EN\0PS_DDR4_VTERM_EN\0PS_DDR4_VPP_2V5_EN\0\0";
				phandle = <0xea>;
			};

			i2c-mux@75 {
				compatible = "nxp,pca9544";
				#address-cells = <0x01>;
				#size-cells = <0x00>;
				reg = <0x75>;

				i2c@0 {
					#address-cells = <0x01>;
					#size-cells = <0x00>;
					reg = <0x00>;

					ina226@40 {
						compatible = "ti,ina226";
						#io-channel-cells = <0x01>;
						label = "ina226-u76";
						reg = <0x40>;
						shunt-resistor = <0x1388>;
						phandle = <0xb2>;
					};

					ina226@41 {
						compatible = "ti,ina226";
						#io-channel-cells = <0x01>;
						label = "ina226-u77";
						reg = <0x41>;
						shunt-resistor = <0x1388>;
						phandle = <0xb3>;
					};

					ina226@42 {
						compatible = "ti,ina226";
						#io-channel-cells = <0x01>;
						label = "ina226-u78";
						reg = <0x42>;
						shunt-resistor = <0x1388>;
						phandle = <0xb4>;
					};

					ina226@43 {
						compatible = "ti,ina226";
						#io-channel-cells = <0x01>;
						label = "ina226-u87";
						reg = <0x43>;
						shunt-resistor = <0x1388>;
						phandle = <0xb5>;
					};

					ina226@44 {
						compatible = "ti,ina226";
						#io-channel-cells = <0x01>;
						label = "ina226-u85";
						reg = <0x44>;
						shunt-resistor = <0x1388>;
						phandle = <0xb6>;
					};

					ina226@45 {
						compatible = "ti,ina226";
						#io-channel-cells = <0x01>;
						label = "ina226-u86";
						reg = <0x45>;
						shunt-resistor = <0x1388>;
						phandle = <0xb7>;
					};

					ina226@46 {
						compatible = "ti,ina226";
						#io-channel-cells = <0x01>;
						label = "ina226-u93";
						reg = <0x46>;
						shunt-resistor = <0x1388>;
						phandle = <0xb8>;
					};

					ina226@47 {
						compatible = "ti,ina226";
						#io-channel-cells = <0x01>;
						label = "ina226-u88";
						reg = <0x47>;
						shunt-resistor = <0x1388>;
						phandle = <0xb9>;
					};

					ina226@4a {
						compatible = "ti,ina226";
						#io-channel-cells = <0x01>;
						label = "ina226-u15";
						reg = <0x4a>;
						shunt-resistor = <0x1388>;
						phandle = <0xba>;
					};

					ina226@4b {
						compatible = "ti,ina226";
						#io-channel-cells = <0x01>;
						label = "ina226-u92";
						reg = <0x4b>;
						shunt-resistor = <0x1388>;
						phandle = <0xbb>;
					};
				};

				i2c@1 {
					#address-cells = <0x01>;
					#size-cells = <0x00>;
					reg = <0x01>;

					ina226@40 {
						compatible = "ti,ina226";
						#io-channel-cells = <0x01>;
						label = "ina226-u79";
						reg = <0x40>;
						shunt-resistor = <0x7d0>;
						phandle = <0xbc>;
					};

					ina226@41 {
						compatible = "ti,ina226";
						#io-channel-cells = <0x01>;
						label = "ina226-u81";
						reg = <0x41>;
						shunt-resistor = <0x1388>;
						phandle = <0xbd>;
					};

					ina226@42 {
						compatible = "ti,ina226";
						#io-channel-cells = <0x01>;
						label = "ina226-u80";
						reg = <0x42>;
						shunt-resistor = <0x1388>;
						phandle = <0xbe>;
					};

					ina226@43 {
						compatible = "ti,ina226";
						#io-channel-cells = <0x01>;
						label = "ina226-u84";
						reg = <0x43>;
						shunt-resistor = <0x1388>;
						phandle = <0xbf>;
					};

					ina226@44 {
						compatible = "ti,ina226";
						#io-channel-cells = <0x01>;
						label = "ina226-u16";
						reg = <0x44>;
						shunt-resistor = <0x1388>;
						phandle = <0xc0>;
					};

					ina226@45 {
						compatible = "ti,ina226";
						#io-channel-cells = <0x01>;
						label = "ina226-u65";
						reg = <0x45>;
						shunt-resistor = <0x1388>;
						phandle = <0xc1>;
					};

					ina226@46 {
						compatible = "ti,ina226";
						#io-channel-cells = <0x01>;
						label = "ina226-u74";
						reg = <0x46>;
						shunt-resistor = <0x1388>;
						phandle = <0xc2>;
					};

					ina226@47 {
						compatible = "ti,ina226";
						#io-channel-cells = <0x01>;
						label = "ina226-u75";
						reg = <0x47>;
						shunt-resistor = <0x1388>;
						phandle = <0xc3>;
					};
				};

				i2c@2 {
					#address-cells = <0x01>;
					#size-cells = <0x00>;
					reg = <0x02>;

					max15301@a {
						compatible = "maxim,max15301";
						reg = <0x0a>;
					};

					max15303@b {
						compatible = "maxim,max15303";
						reg = <0x0b>;
					};

					max15303@10 {
						compatible = "maxim,max15303";
						reg = <0x10>;
					};

					max15301@13 {
						compatible = "maxim,max15301";
						reg = <0x13>;
					};

					max15303@14 {
						compatible = "maxim,max15303";
						reg = <0x14>;
					};

					max15303@15 {
						compatible = "maxim,max15303";
						reg = <0x15>;
					};

					max15303@16 {
						compatible = "maxim,max15303";
						reg = <0x16>;
					};

					max15303@17 {
						compatible = "maxim,max15303";
						reg = <0x17>;
					};

					max15301@18 {
						compatible = "maxim,max15301";
						reg = <0x18>;
					};

					max15303@1a {
						compatible = "maxim,max15303";
						reg = <0x1a>;
					};

					max15303@1d {
						compatible = "maxim,max15303";
						reg = <0x1d>;
					};

					max20751@72 {
						compatible = "maxim,max20751";
						reg = <0x72>;
					};

					max20751@73 {
						compatible = "maxim,max20751";
						reg = <0x73>;
					};

					max15303@1b {
						compatible = "maxim,max15303";
						reg = <0x1b>;
					};
				};
			};
		};

		i2c@ff030000 {
			compatible = "cdns,i2c-r1p14";
			status = "okay";
			interrupt-parent = <0x0c>;
			interrupts = <0x00 0x12 0x04>;
			clock-frequency = <0x61a80>;
			reg = <0x00 0xff030000 0x00 0x1000>;
			#address-cells = <0x01>;
			#size-cells = <0x00>;
			power-domains = <0x84 0x26>;
			clocks = <0x7b 0x3e>;
			xlnx,i2c-reset = <0x00>;
			xlnx,has-interrupt = <0x2faf080>;
			xlnx,clock-freq = <0x5f5b9f5>;
			xlnx,i2c-clk-freq-hz = <0x5f5b9f5>;
			xlnx,ip-name = "psu_i2c";
			xlnx,iic-board-interface = "custom";
			pinctrl-names = "default\0gpio";
			pinctrl-0 = <0xa2>;
			pinctrl-1 = <0xa3>;
			scl-gpios = <0x45 0x10 0x06>;
			sda-gpios = <0x45 0x11 0x06>;
			phandle = <0x48>;

			i2c-mux@74 {
				compatible = "nxp,pca9548";
				#address-cells = <0x01>;
				#size-cells = <0x00>;
				reg = <0x74>;

				i2c@0 {
					#address-cells = <0x01>;
					#size-cells = <0x00>;
					reg = <0x00>;

					eeprom@54 {
						compatible = "atmel,24c08";
						reg = <0x54>;
						#address-cells = <0x01>;
						#size-cells = <0x01>;
						phandle = <0xeb>;

						board-sn@0 {
							reg = <0x00 0x14>;
							phandle = <0xec>;
						};

						eth-mac@20 {
							reg = <0x20 0x06>;
							phandle = <0xed>;
						};

						board-name@d0 {
							reg = <0xd0 0x06>;
							phandle = <0xee>;
						};

						board-revision@e0 {
							reg = <0xe0 0x03>;
							phandle = <0xef>;
						};
					};
				};

				i2c@1 {
					#address-cells = <0x01>;
					#size-cells = <0x00>;
					reg = <0x01>;

					clock-generator@36 {
						compatible = "silabs,si5341";
						reg = <0x36>;
						#clock-cells = <0x02>;
						#address-cells = <0x01>;
						#size-cells = <0x00>;
						clocks = <0xa4>;
						clock-names = "xtal";
						clock-output-names = "si5341";
						phandle = <0xa7>;

						out@0 {
							reg = <0x00>;
							always-on;
							phandle = <0xf0>;
						};

						out@2 {
							reg = <0x02>;
							always-on;
							phandle = <0xf1>;
						};

						out@3 {
							reg = <0x03>;
							always-on;
							phandle = <0xf2>;
						};

						out@4 {
							reg = <0x04>;
							always-on;
							phandle = <0xf3>;
						};

						out@5 {
							reg = <0x05>;
							always-on;
							phandle = <0xf4>;
						};

						out@6 {
							reg = <0x06>;
							always-on;
							phandle = <0xf5>;
						};

						out@7 {
							reg = <0x07>;
							always-on;
							phandle = <0xf6>;
						};

						out@9 {
							reg = <0x09>;
							always-on;
							phandle = <0xf7>;
						};
					};
				};

				i2c@2 {
					#address-cells = <0x01>;
					#size-cells = <0x00>;
					reg = <0x02>;

					clock-generator@5d {
						#clock-cells = <0x00>;
						compatible = "silabs,si570";
						reg = <0x5d>;
						temperature-stability = <0x32>;
						factory-fout = <0x11e1a300>;
						clock-frequency = <0x11e1a300>;
						clock-output-names = "si570_user";
						phandle = <0xf8>;
					};
				};

				i2c@3 {
					#address-cells = <0x01>;
					#size-cells = <0x00>;
					reg = <0x03>;

					clock-generator@5d {
						#clock-cells = <0x00>;
						compatible = "silabs,si570";
						reg = <0x5d>;
						temperature-stability = <0x32>;
						factory-fout = <0x9502f90>;
						clock-frequency = <0x9502f90>;
						clock-output-names = "si570_mgt";
						phandle = <0xf9>;
					};
				};

				i2c@4 {
					#address-cells = <0x01>;
					#size-cells = <0x00>;
					reg = <0x04>;

					clock-generator@69 {
						compatible = "silabs,si5328";
						reg = <0x69>;
						#address-cells = <0x01>;
						#size-cells = <0x00>;
						#clock-cells = <0x01>;
						clocks = <0xa5>;
						clock-names = "xtal";
						clock-output-names = "si5328";
						phandle = <0xfa>;

						clk0@0 {
							reg = <0x00>;
							clock-frequency = <0x19bfcc0>;
							phandle = <0xfb>;
						};
					};
				};
			};

			i2c-mux@75 {
				compatible = "nxp,pca9548";
				#address-cells = <0x01>;
				#size-cells = <0x00>;
				reg = <0x75>;

				i2c@0 {
					#address-cells = <0x01>;
					#size-cells = <0x00>;
					reg = <0x00>;
				};

				i2c@1 {
					#address-cells = <0x01>;
					#size-cells = <0x00>;
					reg = <0x01>;
				};

				i2c@2 {
					#address-cells = <0x01>;
					#size-cells = <0x00>;
					reg = <0x02>;
				};

				i2c@3 {
					#address-cells = <0x01>;
					#size-cells = <0x00>;
					reg = <0x03>;
				};

				i2c@4 {
					#address-cells = <0x01>;
					#size-cells = <0x00>;
					reg = <0x04>;
				};

				i2c@5 {
					#address-cells = <0x01>;
					#size-cells = <0x00>;
					reg = <0x05>;
				};

				i2c@6 {
					#address-cells = <0x01>;
					#size-cells = <0x00>;
					reg = <0x06>;
				};

				i2c@7 {
					#address-cells = <0x01>;
					#size-cells = <0x00>;
					reg = <0x07>;
				};
			};
		};

		memory-controller@ff960000 {
			compatible = "xlnx,zynqmp-ocmc-1.0";
			reg = <0x00 0xff960000 0x00 0x1000>;
			interrupt-parent = <0x0c>;
			interrupts = <0x00 0x0a 0x04>;
			status = "okay";
			xlnx,ip-name = "psu_ocm";
			phandle = <0x55>;
		};

		perf-monitor@ffa00000 {
			compatible = "xlnx,axi-perf-monitor";
			reg = <0x00 0xffa00000 0x00 0x10000>;
			interrupts = <0x00 0x19 0x04>;
			interrupt-parent = <0x0c>;
			xlnx,enable-profile = <0x00>;
			xlnx,enable-trace = <0x00>;
			xlnx,num-monitor-slots = <0x01>;
			xlnx,enable-event-count = <0x01>;
			xlnx,enable-event-log = <0x00>;
			xlnx,have-sampled-metric-cnt = <0x01>;
			xlnx,num-of-counters = <0x03>;
			xlnx,metric-count-width = <0x20>;
			xlnx,metrics-sample-count-width = <0x20>;
			xlnx,global-count-width = <0x20>;
			xlnx,metric-count-scale = <0x01>;
			clocks = <0x7b 0x1f>;
			xlnx,enable-32bit-filter-id = <0x01>;
			xlnx,ip-name = "psu_apm";
			xlnx,fifo-axis-tid-width = <0x01>;
			xlnx,enable-advanced = <0x01>;
			xlnx,can-clk-freq-hz = <0x2faf080>;
			status = "okay";
			xlnx,fifo-axis-tdata-width = <0x38>;
			xlnx,fifo-axis-depth = <0x20>;
			phandle = <0x1e>;
		};

		perf-monitor@fd0b0000 {
			compatible = "xlnx,axi-perf-monitor";
			reg = <0x00 0xfd0b0000 0x00 0x10000>;
			interrupts = <0x00 0x7b 0x04>;
			interrupt-parent = <0x0c>;
			xlnx,enable-profile = <0x00>;
			xlnx,enable-trace = <0x00>;
			xlnx,num-monitor-slots = <0x06>;
			xlnx,enable-event-count = <0x01>;
			xlnx,enable-event-log = <0x00>;
			xlnx,have-sampled-metric-cnt = <0x01>;
			xlnx,num-of-counters = <0x0a>;
			xlnx,metric-count-width = <0x20>;
			xlnx,metrics-sample-count-width = <0x20>;
			xlnx,global-count-width = <0x20>;
			xlnx,metric-count-scale = <0x01>;
			clocks = <0x7b 0x1c>;
			xlnx,enable-32bit-filter-id = <0x01>;
			xlnx,ip-name = "psu_apm";
			xlnx,fifo-axis-tid-width = <0x01>;
			xlnx,enable-advanced = <0x01>;
			xlnx,can-clk-freq-hz = <0x2faf080>;
			status = "okay";
			xlnx,fifo-axis-tdata-width = <0x38>;
			xlnx,fifo-axis-depth = <0x20>;
			phandle = <0x1d>;
		};

		perf-monitor@fd490000 {
			compatible = "xlnx,axi-perf-monitor";
			reg = <0x00 0xfd490000 0x00 0x10000>;
			interrupts = <0x00 0x7b 0x04>;
			interrupt-parent = <0x0c>;
			xlnx,enable-profile = <0x00>;
			xlnx,enable-trace = <0x00>;
			xlnx,num-monitor-slots = <0x01>;
			xlnx,enable-event-count = <0x01>;
			xlnx,enable-event-log = <0x00>;
			xlnx,have-sampled-metric-cnt = <0x01>;
			xlnx,num-of-counters = <0x03>;
			xlnx,metric-count-width = <0x20>;
			xlnx,metrics-sample-count-width = <0x20>;
			xlnx,global-count-width = <0x20>;
			xlnx,metric-count-scale = <0x01>;
			clocks = <0x7b 0x1c>;
			xlnx,enable-32bit-filter-id = <0x01>;
			xlnx,ip-name = "psu_apm";
			xlnx,fifo-axis-tid-width = <0x01>;
			xlnx,enable-advanced = <0x01>;
			xlnx,can-clk-freq-hz = <0x2faf080>;
			status = "okay";
			xlnx,fifo-axis-tdata-width = <0x38>;
			xlnx,fifo-axis-depth = <0x20>;
			phandle = <0x20>;
		};

		perf-monitor@ffa10000 {
			compatible = "xlnx,axi-perf-monitor";
			reg = <0x00 0xffa10000 0x00 0x10000>;
			interrupts = <0x00 0x19 0x04>;
			interrupt-parent = <0x0c>;
			xlnx,enable-profile = <0x00>;
			xlnx,enable-trace = <0x00>;
			xlnx,num-monitor-slots = <0x01>;
			xlnx,enable-event-count = <0x01>;
			xlnx,enable-event-log = <0x00>;
			xlnx,have-sampled-metric-cnt = <0x01>;
			xlnx,num-of-counters = <0x03>;
			xlnx,metric-count-width = <0x20>;
			xlnx,metrics-sample-count-width = <0x20>;
			xlnx,global-count-width = <0x20>;
			xlnx,metric-count-scale = <0x01>;
			clocks = <0x7b 0x1f>;
			xlnx,enable-32bit-filter-id = <0x01>;
			xlnx,ip-name = "psu_apm";
			xlnx,fifo-axis-tid-width = <0x01>;
			xlnx,enable-advanced = <0x01>;
			xlnx,can-clk-freq-hz = <0x2faf080>;
			status = "okay";
			xlnx,fifo-axis-tdata-width = <0x38>;
			xlnx,fifo-axis-depth = <0x20>;
			phandle = <0x1f>;
		};

		pcie@fd0e0000 {
			compatible = "xlnx,nwl-pcie-2.11";
			status = "okay";
			#address-cells = <0x03>;
			#size-cells = <0x02>;
			#interrupt-cells = <0x01>;
			msi-controller;
			device_type = "pci";
			interrupt-parent = <0x0c>;
			interrupts = <0x00 0x76 0x04 0x00 0x75 0x04 0x00 0x74 0x04 0x00 0x73 0x04 0x00 0x72 0x04>;
			interrupt-names = "misc\0dummy\0intx\0msi1\0msi0";
			msi-parent = <0x57>;
			reg = <0x00 0xfd0e0000 0x00 0x1000 0x00 0xfd480000 0x00 0x1000 0x80 0x00 0x00 0x10000000>;
			reg-names = "breg\0pcireg\0cfg";
			ranges = <0x2000000 0x00 0xe0000000 0x00 0xe0000000 0x00 0x10000000 0x43000000 0x06 0x00 0x06 0x00 0x02 0x00>;
			bus-range = <0x00 0xff>;
			interrupt-map-mask = <0x00 0x00 0x00 0x07>;
			interrupt-map = <0x00 0x00 0x00 0x01 0xa6 0x01 0x00 0x00 0x00 0x02 0xa6 0x02 0x00 0x00 0x00 0x03 0xa6 0x03 0x00 0x00 0x00 0x04 0xa6 0x04>;
			power-domains = <0x84 0x3b>;
			clocks = <0x7b 0x17>;
			xlnx,is-cache-coherent = <0x00>;
			xlnx,dma-addr = <0xfd0f0000>;
			xlnx,bar1-enable = <0x00>;
			xlnx,pcie-mode = "Root , Port";
			xlnx,port-type = <0x01>;
			xlnx,bar3-enable = <0x00>;
			xlnx,tz-nonsecure = <0x00>;
			xlnx,bar5-enable = <0x00>;
			xlnx,ip-name = "psu_pcie";
			xlnx,bar0-enable = <0x00>;
			xlnx,bar2-enable = <0x00>;
			xlnx,pcie-board-interface = "custom";
			xlnx,bar4-enable = <0x00>;
			phandle = <0x57>;

			legacy-interrupt-controller {
				interrupt-controller;
				#address-cells = <0x00>;
				#interrupt-cells = <0x01>;
				phandle = <0xa6>;
			};
		};

		spi@ff0f0000 {
			bootph-all;
			compatible = "xlnx,zynqmp-qspi-1.0";
			status = "okay";
			clock-names = "ref_clk\0pclk";
			interrupts = <0x00 0x0f 0x04>;
			interrupt-parent = <0x0c>;
			num-cs = <0x02>;
			reg = <0x00 0xff0f0000 0x00 0x1000 0x00 0xc0000000 0x00 0x8000000>;
			#address-cells = <0x01>;
			#size-cells = <0x00>;
			power-domains = <0x84 0x2d>;
			clocks = <0x7b 0x35 0x7b 0x1f>;
			xlnx,is-cache-coherent = <0x00>;
			xlnx,tz-nonsecure = <0x01>;
			xlnx,qspi-clk-freq-hz = <0x7732877>;
			xlnx,bus-width = <0x02>;
			xlnx,ip-name = "psu_qspi";
			xlnx,qspi-board-interface = "custom";
			spi-rx-bus-width = <0x04>;
			xlnx,connection-mode = <0x02>;
			spi-tx-bus-width = <0x04>;
			qspi-fbclk = <0x00>;
			xlnx,clock-freq = <0x7732877>;
			xlnx,fb-clk = <0x01>;
			xlnx,qspi-mode = <0x02>;
			is-dual = <0x01>;
			xlnx,qspi-bus-width = <0x02>;
			phandle = <0x5e>;

			flash@0 {
				compatible = "m25p80\0jedec,spi-nor";
				#address-cells = <0x01>;
				#size-cells = <0x01>;
				reg = <0x00 0x01>;
				parallel-memories = <0x00 0x4000000 0x00 0x4000000>;
				spi-tx-bus-width = <0x04>;
				spi-rx-bus-width = <0x04>;
				spi-max-frequency = <0x66ff300>;
				phandle = <0x02>;

				partition@0 {
					label = "qspi-boot";
					reg = <0x00 0x1e00000>;
				};

				partition@1 {
					label = "qspi-bootenv";
					reg = <0x1e00000 0x40000>;
				};

				partition@2 {
					label = "qspi-kernel";
					reg = <0x1e40000 0x2400000>;
				};
			};
		};

		phy@fd400000 {
			compatible = "xlnx,zynqmp-psgtr-v1.1";
			status = "okay";
			reg = <0x00 0xfd400000 0x00 0x40000 0x00 0xfd3d0000 0x00 0x1000>;
			reg-names = "serdes\0siou";
			#phy-cells = <0x04>;
			xlnx,ip-name = "psu_serdes";
			clocks = <0xa7 0x00 0x05 0xa7 0x00 0x03 0xa7 0x00 0x02 0xa7 0x00 0x00>;
			clock-names = "ref0\0ref1\0ref2\0ref3";
			phandle = <0x6a>;
		};

		rtc@ffa60000 {
			compatible = "xlnx,zynqmp-rtc";
			status = "okay";
			reg = <0x00 0xffa60000 0x00 0x100>;
			interrupt-parent = <0x0c>;
			interrupts = <0x00 0x1a 0x04 0x00 0x1b 0x04>;
			interrupt-names = "alarm\0sec";
			calibration = <0x7fff>;
			xlnx,ip-name = "psu_rtc";
			phandle = <0x67>;
		};

		ahci@fd0c0000 {
			compatible = "ceva,ahci-1v84";
			status = "okay";
			reg = <0x00 0xfd0c0000 0x00 0x2000>;
			interrupt-parent = <0x0c>;
			interrupts = <0x00 0x85 0x04>;
			power-domains = <0x84 0x1c>;
			resets = <0x03 0x10>;
			clocks = <0x7b 0x16>;
			xlnx,is-cache-coherent = <0x00>;
			xlnx,tz-nonsecure-sata0 = <0x00>;
			xlnx,ip-name = "psu_sata";
			xlnx,sata-board-interface = "custom";
			xlnx,tz-nonsecure-sata1 = <0x00>;
			ceva,p0-cominit-params = <0x18401828>;
			ceva,p0-comwake-params = <0x614080e>;
			ceva,p0-burst-params = <0x13084a06>;
			ceva,p0-retry-params = <0x96a43ffc>;
			ceva,p1-cominit-params = <0x18401828>;
			ceva,p1-comwake-params = <0x614080e>;
			ceva,p1-burst-params = <0x13084a06>;
			ceva,p1-retry-params = <0x96a43ffc>;
			phy-names = "sata-phy";
			phys = <0x6a 0x03 0x01 0x01 0x01>;
			phandle = <0x68>;
		};

		mmc@ff160000 {
			bootph-all;
			compatible = "xlnx,zynqmp-8.9a\0arasan,sdhci-8.9a";
			status = "disabled";
			interrupt-parent = <0x0c>;
			interrupts = <0x00 0x30 0x04>;
			reg = <0x00 0xff160000 0x00 0x1000>;
			clock-names = "clk_xin\0clk_ahb";
			#clock-cells = <0x01>;
			clock-output-names = "clk_out_sd0\0clk_in_sd0";
			power-domains = <0x84 0x27>;
			resets = <0x03 0x26>;
			clocks = <0x7b 0x36 0x7b 0x1f>;
			assigned-clocks = <0x7b 0x36>;
			phandle = <0xfc>;
		};

		mmc@ff170000 {
			bootph-all;
			compatible = "xlnx,zynqmp-8.9a\0arasan,sdhci-8.9a";
			status = "okay";
			interrupt-parent = <0x0c>;
			interrupts = <0x00 0x31 0x04>;
			reg = <0x00 0xff170000 0x00 0x1000>;
			clock-names = "clk_xin\0clk_ahb";
			#clock-cells = <0x01>;
			clock-output-names = "clk_out_sd1\0clk_in_sd1";
			power-domains = <0x84 0x28>;
			resets = <0x03 0x27>;
			clocks = <0x7b 0x37 0x7b 0x1f>;
			assigned-clocks = <0x7b 0x37>;
			xlnx,sd-board-interface = "custom";
			xlnx,is-cache-coherent = <0x00>;
			xlnx,clk-50-ddr-otap-dly = <0x04>;
			xlnx,clk-50-sdr-itap-dly = <0x15>;
			xlnx,has-emio = <0x00>;
			clock-frequency = <0xb2cbcae>;
			xlnx,tz-nonsecure = <0x01>;
			xlnx,clk-100-sdr-otap-dly = <0x03>;
			xlnx,mio-bank = <0x01>;
			xlnx,ip-name = "psu_sd";
			xlnx,bus-width = <0x08>;
			xlnx,card-detect = <0x01>;
			xlnx,has-wp = <0x01>;
			xlnx,has-cd = <0x01>;
			xlnx,slot-type = <0x03>;
			xlnx,clk-50-sdr-otap-dly = <0x05>;
			xlnx,clk-50-ddr-itap-dly = <0x3d>;
			xlnx,has-power = <0x01>;
			xlnx,clk-200-sdr-otap-dly = <0x03>;
			xlnx,sdio-clk-freq-hz = <0xb2cbcae>;
			xlnx,write-protect = <0x01>;
			no-1-8-v;
			pinctrl-names = "default";
			pinctrl-0 = <0xa8>;
			phandle = <0x69>;
		};

		iommu@fd800000 {
			compatible = "arm,mmu-500";
			reg = <0x00 0xfd800000 0x00 0x20000>;
			#iommu-cells = <0x01>;
			status = "okay";
			#global-interrupts = <0x01>;
			interrupt-parent = <0x0c>;
			interrupts = <0x00 0x9b 0x04 0x00 0x9b 0x04 0x00 0x9b 0x04 0x00 0x9b 0x04 0x00 0x9b 0x04 0x00 0x9b 0x04 0x00 0x9b 0x04 0x00 0x9b 0x04 0x00 0x9b 0x04 0x00 0x9b 0x04 0x00 0x9b 0x04 0x00 0x9b 0x04 0x00 0x9b 0x04 0x00 0x9b 0x04 0x00 0x9b 0x04 0x00 0x9b 0x04 0x00 0x9b 0x04>;
			xlnx,ip-name = "psu_smmu_gpv";
			phandle = <0x6c>;
		};

		spi@ff040000 {
			compatible = "cdns,spi-r1p6";
			status = "disabled";
			interrupt-parent = <0x0c>;
			interrupts = <0x00 0x13 0x04>;
			reg = <0x00 0xff040000 0x00 0x1000>;
			clock-names = "ref_clk\0pclk";
			#address-cells = <0x01>;
			#size-cells = <0x00>;
			power-domains = <0x84 0x23>;
			clocks = <0x7b 0x3a 0x7b 0x1f>;
			phandle = <0xfd>;
		};

		spi@ff050000 {
			compatible = "cdns,spi-r1p6";
			status = "disabled";
			interrupt-parent = <0x0c>;
			interrupts = <0x00 0x14 0x04>;
			reg = <0x00 0xff050000 0x00 0x1000>;
			clock-names = "ref_clk\0pclk";
			#address-cells = <0x01>;
			#size-cells = <0x00>;
			power-domains = <0x84 0x24>;
			clocks = <0x7b 0x3b 0x7b 0x1f>;
			phandle = <0xfe>;
		};

		timer@ff110000 {
			compatible = "cdns,ttc";
			status = "okay";
			interrupt-parent = <0x0c>;
			interrupts = <0x00 0x24 0x04 0x00 0x25 0x04 0x00 0x26 0x04>;
			reg = <0x00 0xff110000 0x00 0x1000>;
			timer-width = <0x20>;
			power-domains = <0x84 0x18>;
			clocks = <0x7b 0x1f>;
			xlnx,ttc-board-interface = "custom";
			xlnx,ttc-clk2-freq-hz = <0x5f5e100>;
			xlnx,clock-freq = <0x5f5e100>;
			xlnx,ip-name = "psu_ttc";
			xlnx,ttc-clk0-freq-hz = <0x5f5e100>;
			xlnx,ttc-clk1-freq-hz = <0x5f5e100>;
			phandle = <0x6e>;
		};

		timer@ff120000 {
			compatible = "cdns,ttc";
			status = "okay";
			interrupt-parent = <0x0c>;
			interrupts = <0x00 0x27 0x04 0x00 0x28 0x04 0x00 0x29 0x04>;
			reg = <0x00 0xff120000 0x00 0x1000>;
			timer-width = <0x20>;
			power-domains = <0x84 0x19>;
			clocks = <0x7b 0x1f>;
			xlnx,ttc-board-interface = "custom";
			xlnx,ttc-clk2-freq-hz = <0x5f5e100>;
			xlnx,clock-freq = <0x5f5e100>;
			xlnx,ip-name = "psu_ttc";
			xlnx,ttc-clk0-freq-hz = <0x5f5e100>;
			xlnx,ttc-clk1-freq-hz = <0x5f5e100>;
			phandle = <0x6f>;
		};

		timer@ff130000 {
			compatible = "cdns,ttc";
			status = "okay";
			interrupt-parent = <0x0c>;
			interrupts = <0x00 0x2a 0x04 0x00 0x2b 0x04 0x00 0x2c 0x04>;
			reg = <0x00 0xff130000 0x00 0x1000>;
			timer-width = <0x20>;
			power-domains = <0x84 0x1a>;
			clocks = <0x7b 0x1f>;
			xlnx,ttc-board-interface = "custom";
			xlnx,ttc-clk2-freq-hz = <0x5f5e100>;
			xlnx,clock-freq = <0x5f5e100>;
			xlnx,ip-name = "psu_ttc";
			xlnx,ttc-clk0-freq-hz = <0x5f5e100>;
			xlnx,ttc-clk1-freq-hz = <0x5f5e100>;
			phandle = <0x70>;
		};

		timer@ff140000 {
			compatible = "cdns,ttc";
			status = "okay";
			interrupt-parent = <0x0c>;
			interrupts = <0x00 0x2d 0x04 0x00 0x2e 0x04 0x00 0x2f 0x04>;
			reg = <0x00 0xff140000 0x00 0x1000>;
			timer-width = <0x20>;
			power-domains = <0x84 0x1b>;
			clocks = <0x7b 0x1f>;
			xlnx,ttc-board-interface = "custom";
			xlnx,ttc-clk2-freq-hz = <0x5f5e100>;
			xlnx,clock-freq = <0x5f5e100>;
			xlnx,ip-name = "psu_ttc";
			xlnx,ttc-clk0-freq-hz = <0x5f5e100>;
			xlnx,ttc-clk1-freq-hz = <0x5f5e100>;
			phandle = <0x71>;
		};

		serial@ff000000 {
			bootph-all;
			compatible = "xlnx,zynqmp-uart\0cdns,uart-r1p12";
			status = "okay";
			interrupt-parent = <0x0c>;
			interrupts = <0x00 0x15 0x04>;
			reg = <0x00 0xff000000 0x00 0x1000>;
			clock-names = "uart_clk\0pclk";
			power-domains = <0x84 0x21>;
			resets = <0x03 0x22>;
			clocks = <0x7b 0x38 0x7b 0x1f>;
			assigned-clocks = <0x7b 0x38>;
			xlnx,has-modem = <0x00>;
			xlnx,uart-clk-freq-hz = <0x5f5b9f5>;
			port-number = <0x00>;
			xlnx,ip-name = "psu_uart";
			xlnx,uart-board-interface = "custom";
			xlnx,baudrate = <0x1c200>;
			cts-override;
			u-boot,dm-pre-reloc;
			xlnx,clock-freq = <0x5f5b9f5>;
			pinctrl-names = "default";
			pinctrl-0 = <0xa9>;
			phandle = <0x72>;
		};

		serial@ff010000 {
			bootph-all;
			compatible = "xlnx,zynqmp-uart\0cdns,uart-r1p12";
			status = "okay";
			interrupt-parent = <0x0c>;
			interrupts = <0x00 0x16 0x04>;
			reg = <0x00 0xff010000 0x00 0x1000>;
			clock-names = "uart_clk\0pclk";
			power-domains = <0x84 0x22>;
			resets = <0x03 0x23>;
			clocks = <0x7b 0x39 0x7b 0x1f>;
			assigned-clocks = <0x7b 0x39>;
			xlnx,has-modem = <0x00>;
			xlnx,uart-clk-freq-hz = <0x5f5b9f5>;
			port-number = <0x00>;
			xlnx,ip-name = "psu_uart";
			xlnx,uart-board-interface = "custom";
			xlnx,baudrate = <0x1c200>;
			cts-override;
			u-boot,dm-pre-reloc;
			xlnx,clock-freq = <0x5f5b9f5>;
			pinctrl-names = "default";
			pinctrl-0 = <0xaa>;
			phandle = <0x73>;
		};

		usb@ff9d0000 {
			#address-cells = <0x02>;
			#size-cells = <0x02>;
			status = "okay";
			compatible = "xlnx,zynqmp-dwc3";
			reg = <0x00 0xff9d0000 0x00 0x100>;
			clock-names = "bus_clk\0ref_clk";
			power-domains = <0x84 0x16>;
			resets = <0x03 0x3b 0x03 0x3d 0x03 0x3f>;
			reset-names = "usb_crst\0usb_hibrst\0usb_apbrst";
			reset-gpios = <0xab 0x01 0x01>;
			ranges;
			clocks = <0x7b 0x20 0x7b 0x22>;
			assigned-clocks = <0x7b 0x20 0x7b 0x22>;
			xlnx,is-cache-coherent = <0x00>;
			xlnx,usb-polarity = <0x00>;
			xlnx,ip-name = "psu_usb";
			xlnx,usb-reset-mode = <0x00>;
			xlnx,usb-board-interface = "custom";
			xlnx,tz-nonsecure = <0x01>;
			pinctrl-names = "default";
			pinctrl-0 = <0xac>;
			phy-names = "usb3-phy";
			phys = <0x6a 0x02 0x04 0x00 0x02>;
			phandle = <0x74>;

			usb@fe200000 {
				compatible = "snps,dwc3";
				status = "okay";
				reg = <0x00 0xfe200000 0x00 0x40000>;
				interrupt-parent = <0x0c>;
				interrupt-names = "host\0peripheral\0otg\0wakeup";
				interrupts = <0x00 0x41 0x04 0x00 0x41 0x04 0x00 0x45 0x04 0x00 0x4b 0x04>;
				snps,quirk-frame-length-adjustment = <0x20>;
				clock-names = "ref";
				snps,resume-hs-terminations;
				clocks = <0x7b 0x22>;
				xlnx,is-cache-coherent = <0x00>;
				xlnx,ip-name = "psu_usb_xhci";
				xlnx,usb-board-interface = "custom";
				dr_mode = "host";
				snps,usb3_lpm_capable;
				maximum-speed = "super-speed";
				phandle = <0x75>;
			};
		};

		usb@ff9e0000 {
			#address-cells = <0x02>;
			#size-cells = <0x02>;
			status = "disabled";
			compatible = "xlnx,zynqmp-dwc3";
			reg = <0x00 0xff9e0000 0x00 0x100>;
			clock-names = "bus_clk\0ref_clk";
			power-domains = <0x84 0x17>;
			resets = <0x03 0x3c 0x03 0x3e 0x03 0x40>;
			reset-names = "usb_crst\0usb_hibrst\0usb_apbrst";
			ranges;
			clocks = <0x7b 0x21 0x7b 0x22>;
			assigned-clocks = <0x7b 0x21 0x7b 0x22>;
			phandle = <0xff>;

			usb@fe300000 {
				compatible = "snps,dwc3";
				status = "disabled";
				reg = <0x00 0xfe300000 0x00 0x40000>;
				interrupt-parent = <0x0c>;
				interrupt-names = "host\0peripheral\0otg\0wakeup";
				interrupts = <0x00 0x46 0x04 0x00 0x46 0x04 0x00 0x4a 0x04 0x00 0x4c 0x04>;
				snps,quirk-frame-length-adjustment = <0x20>;
				clock-names = "ref";
				snps,resume-hs-terminations;
				clocks = <0x7b 0x22>;
				phandle = <0x100>;
			};
		};

		watchdog@fd4d0000 {
			compatible = "cdns,wdt-r1p2";
			status = "okay";
			interrupt-parent = <0x0c>;
			interrupts = <0x00 0x71 0x01>;
			reg = <0x00 0xfd4d0000 0x00 0x1000>;
			timeout-sec = <0x3c>;
			reset-on-timeout;
			clocks = <0x7b 0x4b>;
			xlnx,ip-name = "psu_wdt";
			xlnx,wdt-clk-freq-hz = <0x5f5b9f5>;
			xlnx,swdt-board-interface = "custom";
			phandle = <0x77>;
		};

		watchdog@ff150000 {
			compatible = "cdns,wdt-r1p2";
			status = "okay";
			interrupt-parent = <0x0c>;
			interrupts = <0x00 0x34 0x01>;
			reg = <0x00 0xff150000 0x00 0x1000>;
			timeout-sec = <0x0a>;
			clocks = <0x7b 0x70>;
			xlnx,ip-name = "psu_wdt";
			xlnx,wdt-clk-freq-hz = <0x5f5b9f5>;
			xlnx,swdt-board-interface = "custom";
			phandle = <0x76>;
		};

		ams@ffa50000 {
			compatible = "xlnx,zynqmp-ams";
			status = "okay";
			interrupt-parent = <0x0c>;
			interrupts = <0x00 0x38 0x04>;
			reg = <0x00 0xffa50000 0x00 0x800>;
			#address-cells = <0x01>;
			#size-cells = <0x01>;
			#io-channel-cells = <0x01>;
			ranges = <0x00 0x00 0xffa50800 0x800>;
			clocks = <0x7b 0x46>;
			xlnx,clock-freq = <0x33>;
			xlnx,ip-name = "psu_ams";
			phandle = <0x1c>;

			ams-ps@0 {
				compatible = "xlnx,zynqmp-ams-ps";
				status = "okay";
				reg = <0x00 0x400>;
				phandle = <0x05>;
			};

			ams-pl@400 {
				compatible = "xlnx,zynqmp-ams-pl";
				status = "okay";
				reg = <0x400 0x400>;
				phandle = <0x06>;
			};
		};

		dma-controller@fd4c0000 {
			compatible = "xlnx,zynqmp-dpdma";
			status = "okay";
			reg = <0x00 0xfd4c0000 0x00 0x1000>;
			interrupts = <0x00 0x7a 0x04>;
			interrupt-parent = <0x0c>;
			clock-names = "axi_clk";
			power-domains = <0x84 0x29>;
			dma-channels = <0x06>;
			#dma-cells = <0x01>;
			clocks = <0x7b 0x14>;
			assigned-clocks = <0x7b 0x14>;
			xlnx,ip-name = "psu_dpdma";
			phandle = <0x35>;
		};

		dp-aud@fd4ac000 {
			compatible = "xlnx,zynqmp-dpaud-setting\0syscon";
			reg = <0x00 0xfd4ac000 0x00 0x1000>;
			phandle = <0xad>;
		};

		display@fd4a0000 {
			bootph-all;
			compatible = "xlnx,zynqmp-dpsub-1.7";
			status = "okay";
			reg = <0x00 0xfd4a0000 0x00 0x1000 0x00 0xfd4aa000 0x00 0x1000 0x00 0xfd4ab000 0x00 0x1000>;
			reg-names = "dp\0blend\0av_buf";
			xlnx,dpaud-reg = <0xad>;
			interrupts = <0x00 0x77 0x04>;
			interrupt-parent = <0x0c>;
			clock-names = "dp_apb_clk\0dp_aud_clk\0dp_vtc_pixel_clk_in";
			power-domains = <0x84 0x29>;
			resets = <0x03 0x03>;
			dma-names = "vid0\0vid1\0vid2\0gfx0";
			dmas = <0x35 0x00 0x35 0x01 0x35 0x02 0x35 0x03>;
			clocks = <0x7b 0x1c 0x7b 0x11 0x7b 0x10>;
			assigned-clocks = <0x7b 0x12 0x7b 0x11 0x7b 0x10>;
			xlnx,max-lanes = <0x01>;
			phys = <0x6a 0x01 0x06 0x00 0x03>;
			xlnx,dp-board-interface = "custom";
			xlnx,ip-name = "psu_dp";
			phy-names = "dp-phy0";
			xlnx,tz-nonsecure = <0x00>;
			phandle = <0x34>;

			zynqmp-dp-snd-codec0 {
				compatible = "xlnx,dp-snd-codec";
				clock-names = "aud_clk";
				clocks = <0x7b 0x11>;
				phandle = <0xb0>;
			};

			zynqmp-dp-snd-pcm0 {
				compatible = "xlnx,dp-snd-pcm0";
				dmas = <0x35 0x04>;
				dma-names = "tx";
				phandle = <0xae>;
			};

			zynqmp-dp-snd-pcm1 {
				compatible = "xlnx,dp-snd-pcm1";
				dmas = <0x35 0x05>;
				dma-names = "tx";
				phandle = <0xaf>;
			};

			zynqmp-dp-snd-card {
				compatible = "xlnx,dp-snd-card";
				xlnx,dp-snd-pcm = <0xae 0xaf>;
				xlnx,dp-snd-codec = <0xb0>;
				phandle = <0x101>;
			};
		};

		coresight@fe800000 {
			compatible = "xlnx,coresight-1.0";
			status = "okay";
			reg = <0x00 0xfe800000 0x00 0x10000>;
			xlnx,ip-name = "psu_coresight_0";
			phandle = <0x25>;
		};

		dma@ffc80000 {
			status = "okay";
			compatible = "xlnx,zynqmp-csudma-1.0";
			interrupt-parent = <0x0c>;
			interrupts = <0x00 0x56 0x04>;
			reg = <0x00 0xffc80000 0x00 0x40000>;
			xlnx,ip-name = "psu_csudma";
			xlnx,dma-type = <0x00>;
			phandle = <0x29>;
		};

		ipi@ff360000 {
			status = "disabled";
			compatible = "xlnx,zynqmp-ipi-mailbox";
			interrupt-parent = <0x0c>;
			interrupts = <0x00 0x1f 0x04>;
			reg = <0x00 0xff360000 0x00 0x20>;
			xlnx,ipi-bitmask = <0x4000000>;
			xlnx,ipi-id = <0x09>;
			xlnx,ipi-buf-index = <0x05>;
			#address-cells = <0x02>;
			#size-cells = <0x02>;
			bootph-all;
			ranges;
			phandle = <0x153>;
		};

		ipi@ff370000 {
			status = "disabled";
			compatible = "xlnx,zynqmp-ipi-mailbox";
			interrupt-parent = <0x0c>;
			interrupts = <0x00 0x20 0x04>;
			reg = <0x00 0xff370000 0x00 0x20>;
			xlnx,ipi-bitmask = <0x8000000>;
			xlnx,ipi-id = <0x0a>;
			xlnx,ipi-buf-index = <0x05>;
			#address-cells = <0x02>;
			#size-cells = <0x02>;
			bootph-all;
			ranges;
			phandle = <0x154>;
		};

		psu_csu@ffca0000 {
			xlnx,csu-board-interface = "custom";
			compatible = "xlnx,psu-csu-1.0";
			status = "okay";
			xlnx,can-clk-freq-hz = <0x1dcd6500>;
			xlnx,ip-name = "psu_csu";
			reg = <0x00 0xffca0000 0x00 0x10000>;
			phandle = <0x28>;
		};

		psu_smmu_reg@fd5f0000 {
			compatible = "xlnx,psu-smmu-reg-1.0";
			status = "okay";
			xlnx,ip-name = "psu_smmu_reg";
			reg = <0x00 0xfd5f0000 0x00 0x10000>;
			phandle = <0x6d>;
		};

		psu_cci_reg@fd5e0000 {
			compatible = "xlnx,psu-cci-reg-1.0";
			status = "okay";
			xlnx,ip-name = "psu_cci_reg";
			reg = <0x00 0xfd5e0000 0x00 0x10000>;
			phandle = <0x24>;
		};

		psu_afi@fd3b0000 {
			compatible = "xlnx,psu-afi-1.0";
			status = "okay";
			xlnx,ip-name = "psu_afi";
			reg = <0x00 0xfd3b0000 0x00 0x10000>;
			phandle = <0x1a>;
		};

		psu_afi@fd3a0000 {
			compatible = "xlnx,psu-afi-1.0";
			status = "okay";
			xlnx,ip-name = "psu_afi";
			reg = <0x00 0xfd3a0000 0x00 0x10000>;
			phandle = <0x19>;
		};

		psu_afi@fd390000 {
			compatible = "xlnx,psu-afi-1.0";
			status = "okay";
			xlnx,ip-name = "psu_afi";
			reg = <0x00 0xfd390000 0x00 0x10000>;
			phandle = <0x18>;
		};

		psu_afi@fd380000 {
			compatible = "xlnx,psu-afi-1.0";
			status = "okay";
			xlnx,ip-name = "psu_afi";
			reg = <0x00 0xfd380000 0x00 0x10000>;
			phandle = <0x17>;
		};

		psu_afi@fd370000 {
			compatible = "xlnx,psu-afi-1.0";
			status = "okay";
			xlnx,ip-name = "psu_afi";
			reg = <0x00 0xfd370000 0x00 0x10000>;
			phandle = <0x16>;
		};

		psu_afi@fd360000 {
			compatible = "xlnx,psu-afi-1.0";
			status = "okay";
			xlnx,ip-name = "psu_afi";
			reg = <0x00 0xfd360000 0x00 0x10000>;
			phandle = <0x15>;
		};

		psu_pcie@e0000000 {
			compatible = "xlnx,psu-pcie-1.0";
			status = "okay";
			xlnx,dma-addr = <0xfd0f0000>;
			xlnx,ip-name = "psu_pcie";
			reg = <0x00 0xe0000000 0x00 0x10000000>;
			xlnx,port-type = <0x01>;
			phandle = <0x5c>;
		};

		psu_pcie@600000000 {
			compatible = "xlnx,psu-pcie-1.0";
			status = "okay";
			xlnx,dma-addr = <0xfd0f0000>;
			xlnx,ip-name = "psu_pcie";
			reg = <0x06 0x00 0x02 0x00>;
			xlnx,port-type = <0x01>;
			phandle = <0x5a>;
		};

		psu_pcie@8000000000 {
			compatible = "xlnx,psu-pcie-1.0";
			status = "okay";
			xlnx,dma-addr = <0xfd0f0000>;
			xlnx,ip-name = "psu_pcie";
			reg = <0x80 0x00 0x40 0x00>;
			xlnx,port-type = <0x01>;
			phandle = <0x5b>;
		};

		psu_afi@ff9b0000 {
			compatible = "xlnx,psu-afi-1.0";
			status = "okay";
			xlnx,ip-name = "psu_afi";
			reg = <0x00 0xff9b0000 0x00 0x10000>;
			phandle = <0x1b>;
		};

		PERIPHERAL@ff380000 {
			compatible = "xlnx,PERIPHERAL-1.0";
			reg = <0x00 0xff380000 0x00 0x80000>;
			phandle = <0x2a>;
		};

		PERIPHERAL@ff990000 {
			compatible = "xlnx,PERIPHERAL-1.0";
			reg = <0x00 0xff990000 0x00 0x10000>;
			phandle = <0x54>;
		};

		psu_iouslcr@ff180000 {
			compatible = "xlnx,psu-iouslcr-1.0";
			status = "okay";
			xlnx,ip-name = "psu_iouslcr";
			reg = <0x00 0xff180000 0x00 0xc0000>;
			phandle = <0x4c>;
		};

		psu_qspi_linear@c0000000 {
			reg = <0x00 0xc0000000 0x00 0x20000000>;
			phandle = <0x15b>;
		};

		interrupt-controller@f9010000 {
			phandle = <0x0c>;
			xlnx,ip-name = "psu_acpu_gic";
			status = "okay";
			interrupts = <0x01 0x09 0xf04>;
			interrupt-parent = <0x0c>;
			interrupt-controller;
			reg = <0x00 0xf9010000 0x00 0x10000 0x00 0xf9020000 0x00 0x20000 0x00 0xf9040000 0x00 0x20000 0x00 0xf9060000 0x00 0x20000>;
			#interrupt-cells = <0x03>;
			compatible = "arm,gic-400";
		};
	};

	indirect-bus@1 {
		compatible = "indirect-bus";
		#address-cells = <0x02>;
		#size-cells = <0x02>;
		phandle = <0x15c>;

		xppu@ff980000 {
			compatible = "xlnx,xppu";
			#firewall-cells = <0x00>;
			reg = <0x00 0xff980000 0x00 0x1000>;
			status = "okay";
			xlnx,ip-name = "psu_lpd_xppu";
			phandle = <0x51>;
		};
	};

	pss_ref_clk {
		bootph-all;
		compatible = "fixed-clock";
		#clock-cells = <0x00>;
		clock-frequency = <0x1fc9350>;
		phandle = <0x95>;
	};

	video_clk {
		bootph-all;
		compatible = "fixed-clock";
		#clock-cells = <0x00>;
		clock-frequency = <0x1fc9f08>;
		phandle = <0x96>;
	};

	pss_alt_ref_clk {
		bootph-all;
		compatible = "fixed-clock";
		#clock-cells = <0x00>;
		clock-frequency = <0x00>;
		phandle = <0x97>;
	};

	gt_crx_ref_clk {
		bootph-all;
		compatible = "fixed-clock";
		#clock-cells = <0x00>;
		clock-frequency = <0x66ff300>;
		phandle = <0x99>;
	};

	aux_ref_clk {
		bootph-all;
		compatible = "fixed-clock";
		#clock-cells = <0x00>;
		clock-frequency = <0x19bfcc0>;
		phandle = <0x98>;
	};

	amba_pl {
		ranges;
		compatible = "simple-bus";
		#address-cells = <0x02>;
		#size-cells = <0x02>;
		firmware-name = "project_1.bit.bin";
		phandle = <0x15d>;

		misc_clk_0 {
			clock-div = <0x01>;
			compatible = "fixed-factor-clock";
			clock-mult = <0x01>;
			clocks = <0x7b 0x47>;
			#clock-cells = <0x00>;
			phandle = <0xb1>;
		};

		interrupt-controller@80020000 {
			#interrupt-cells = <0x02>;
			interrupts = <0x00 0x59 0x04>;
			xlnx,sense-of-irq-edge-type = "Rising";
			xlnx,edk-special = "INTR_CTRL";
			xlnx,kind-of-intr = <0x01>;
			xlnx,kind-of-edge = <0xffffffff>;
			xlnx,irq-is-level = <0x01>;
			xlnx,has-ivr = <0x01>;
			compatible = "xlnx,axi-intc-4.1\0xlnx,xps-intc-1.00.a";
			xlnx,disable-synchronizers = <0x00>;
			xlnx,kind-of-lvl = <0xffffffff>;
			xlnx,ivar-reset-value = <0x10>;
			xlnx,irq-active = <0x01>;
			interrupt-parent = <0x0c>;
			xlnx,en-cascade-mode = <0x00>;
			xlnx,ip-name = "axi_intc";
			xlnx,has-ilr = <0x00>;
			reg = <0x00 0x80020000 0x00 0x1000>;
			xlnx,addr-width = <0x20>;
			clocks = <0xb1>;
			xlnx,s-axi-aclk-freq-mhz = <0x4784b74>;
			xlnx,num-sw-intr = <0x00>;
			xlnx,irq-connection = <0x01>;
			xlnx,num-intr-inputs = <0x01>;
			xlnx,has-sie = <0x01>;
			xlnx,enable-async = <0x00>;
			xlnx,has-cie = <0x01>;
			xlnx,num-sync-ff = <0x02>;
			xlnx,edk-iptype = "PERIPHERAL";
			xlnx,mb-clk-not-connected = <0x01>;
			xlnx,has-ipr = <0x01>;
			xlnx,sense-of-irq-level-type = "Active_High";
			xlnx,cascade-master = <0x00>;
			xlnx,processor-clk-freq-mhz = <0x64>;
			status = "okay";
			xlnx,is-fast = <0x00>;
			clock-names = "s_axi_aclk";
			xlnx,has-fast = <0x00>;
			xlnx,ivar-rst-val = <0x10>;
			interrupt-controller;
			interrupt-names = "irq";
			xlnx,async-intr = <0xffffffff>;
			phandle = <0x0b>;
		};
	};

	memory@0 {
		compatible = "xlnx,psu-ddr-1.0";
		xlnx,ip-name = "psu_ddr";
		device_type = "memory";
		memory_type = "memory";
		reg = <0x00 0x00 0x00 0x7ff00000>;
		phandle = <0x09>;
	};

	memory@800000000 {
		compatible = "xlnx,psu-ddr-1.0";
		xlnx,ip-name = "psu_ddr";
		device_type = "memory";
		memory_type = "memory";
		reg = <0x08 0x00 0x00 0x80000000>;
		phandle = <0x0a>;
	};

	chosen {
		bootargs = "earlycon console=ttyPS0,115200 root=/dev/ram0 rw init_fatal_sh=1";
		stdout-path = "serial0:115200n8";
	};

	aliases {
		serial0 = "/axi/serial@ff000000";
		spi0 = "/axi/spi@ff0f0000";
		serial1 = "/axi/serial@ff010000";
		serial2 = "/dcc";
		i2c0 = "/axi/i2c@ff020000";
		i2c1 = "/axi/i2c@ff030000";
		ethernet0 = "/axi/ethernet@ff0e0000";
		mmc0 = "/axi/mmc@ff170000";
		nvmem0 = "/axi/i2c@ff030000/i2c-mux@74/i2c@0/eeprom@54";
		rtc0 = "/axi/rtc@ffa60000";
		usb0 = "/axi/usb@ff9d0000";
	};

	gpio-keys {
		compatible = "gpio-keys";
		autorepeat;

		switch-19 {
			label = "sw19";
			gpios = <0x45 0x16 0x00>;
			linux,code = <0x6c>;
			wakeup-source;
			autorepeat;
		};
	};

	leds {
		compatible = "gpio-leds";

		heartbeat-led {
			label = "heartbeat";
			gpios = <0x45 0x17 0x00>;
			linux,default-trigger = "heartbeat";
		};
	};

	ina226-u76 {
		compatible = "iio-hwmon";
		io-channels = <0xb2 0x00 0xb2 0x01 0xb2 0x02 0xb2 0x03>;
	};

	ina226-u77 {
		compatible = "iio-hwmon";
		io-channels = <0xb3 0x00 0xb3 0x01 0xb3 0x02 0xb3 0x03>;
	};

	ina226-u78 {
		compatible = "iio-hwmon";
		io-channels = <0xb4 0x00 0xb4 0x01 0xb4 0x02 0xb4 0x03>;
	};

	ina226-u87 {
		compatible = "iio-hwmon";
		io-channels = <0xb5 0x00 0xb5 0x01 0xb5 0x02 0xb5 0x03>;
	};

	ina226-u85 {
		compatible = "iio-hwmon";
		io-channels = <0xb6 0x00 0xb6 0x01 0xb6 0x02 0xb6 0x03>;
	};

	ina226-u86 {
		compatible = "iio-hwmon";
		io-channels = <0xb7 0x00 0xb7 0x01 0xb7 0x02 0xb7 0x03>;
	};

	ina226-u93 {
		compatible = "iio-hwmon";
		io-channels = <0xb8 0x00 0xb8 0x01 0xb8 0x02 0xb8 0x03>;
	};

	ina226-u88 {
		compatible = "iio-hwmon";
		io-channels = <0xb9 0x00 0xb9 0x01 0xb9 0x02 0xb9 0x03>;
	};

	ina226-u15 {
		compatible = "iio-hwmon";
		io-channels = <0xba 0x00 0xba 0x01 0xba 0x02 0xba 0x03>;
	};

	ina226-u92 {
		compatible = "iio-hwmon";
		io-channels = <0xbb 0x00 0xbb 0x01 0xbb 0x02 0xbb 0x03>;
	};

	ina226-u79 {
		compatible = "iio-hwmon";
		io-channels = <0xbc 0x00 0xbc 0x01 0xbc 0x02 0xbc 0x03>;
	};

	ina226-u81 {
		compatible = "iio-hwmon";
		io-channels = <0xbd 0x00 0xbd 0x01 0xbd 0x02 0xbd 0x03>;
	};

	ina226-u80 {
		compatible = "iio-hwmon";
		io-channels = <0xbe 0x00 0xbe 0x01 0xbe 0x02 0xbe 0x03>;
	};

	ina226-u84 {
		compatible = "iio-hwmon";
		io-channels = <0xbf 0x00 0xbf 0x01 0xbf 0x02 0xbf 0x03>;
	};

	ina226-u16 {
		compatible = "iio-hwmon";
		io-channels = <0xc0 0x00 0xc0 0x01 0xc0 0x02 0xc0 0x03>;
	};

	ina226-u65 {
		compatible = "iio-hwmon";
		io-channels = <0xc1 0x00 0xc1 0x01 0xc1 0x02 0xc1 0x03>;
	};

	ina226-u74 {
		compatible = "iio-hwmon";
		io-channels = <0xc2 0x00 0xc2 0x01 0xc2 0x02 0xc2 0x03>;
	};

	ina226-u75 {
		compatible = "iio-hwmon";
		io-channels = <0xc3 0x00 0xc3 0x01 0xc3 0x02 0xc3 0x03>;
	};

	ref48M {
		compatible = "fixed-clock";
		#clock-cells = <0x00>;
		clock-frequency = <0x2dc6c00>;
		phandle = <0xa4>;
	};

	refhdmi {
		compatible = "fixed-clock";
		#clock-cells = <0x00>;
		clock-frequency = <0x6cfd9c8>;
		phandle = <0xa5>;
	};

	__symbols__ {
		cpus_a53 = "/cpus-a53@0";
		psu_cortexa53_0 = "/cpus-a53@0/cpu@0";
		psu_cortexa53_1 = "/cpus-a53@0/cpu@1";
		psu_cortexa53_2 = "/cpus-a53@0/cpu@2";
		psu_cortexa53_3 = "/cpus-a53@0/cpu@3";
		L2 = "/cpus-a53@0/l2-cache";
		CPU_SLEEP_0 = "/cpus-a53@0/idle-states/cpu-sleep-0";
		cpu_opp_table = "/opp-table-cpu";
		zynqmp_ipi = "/zynqmp-ipi";
		ipi_mailbox_pmu1 = "/zynqmp-ipi/mailbox@ff9905c0";
		dcc = "/dcc";
		optee = "/firmware/optee";
		zynqmp_firmware = "/firmware/zynqmp-firmware";
		zynqmp_power = "/firmware/zynqmp-firmware/power-management";
		soc_revision = "/firmware/zynqmp-firmware/soc-nvmem/nvmem-layout/soc-revision@0";
		efuse_dna = "/firmware/zynqmp-firmware/soc-nvmem/nvmem-layout/efuse-dna@c";
		efuse_usr0 = "/firmware/zynqmp-firmware/soc-nvmem/nvmem-layout/efuse-usr0@20";
		efuse_usr1 = "/firmware/zynqmp-firmware/soc-nvmem/nvmem-layout/efuse-usr1@24";
		efuse_usr2 = "/firmware/zynqmp-firmware/soc-nvmem/nvmem-layout/efuse-usr2@28";
		efuse_usr3 = "/firmware/zynqmp-firmware/soc-nvmem/nvmem-layout/efuse-usr3@2c";
		efuse_usr4 = "/firmware/zynqmp-firmware/soc-nvmem/nvmem-layout/efuse-usr4@30";
		efuse_usr5 = "/firmware/zynqmp-firmware/soc-nvmem/nvmem-layout/efuse-usr5@34";
		efuse_usr6 = "/firmware/zynqmp-firmware/soc-nvmem/nvmem-layout/efuse-usr6@38";
		efuse_usr7 = "/firmware/zynqmp-firmware/soc-nvmem/nvmem-layout/efuse-usr7@3c";
		efuse_miscusr = "/firmware/zynqmp-firmware/soc-nvmem/nvmem-layout/efuse-miscusr@40";
		efuse_chash = "/firmware/zynqmp-firmware/soc-nvmem/nvmem-layout/efuse-chash@50";
		efuse_pufmisc = "/firmware/zynqmp-firmware/soc-nvmem/nvmem-layout/efuse-pufmisc@54";
		efuse_sec = "/firmware/zynqmp-firmware/soc-nvmem/nvmem-layout/efuse-sec@58";
		efuse_spkid = "/firmware/zynqmp-firmware/soc-nvmem/nvmem-layout/efuse-spkid@5c";
		efuse_aeskey = "/firmware/zynqmp-firmware/soc-nvmem/nvmem-layout/efuse-aeskey@60";
		efuse_ppk0hash = "/firmware/zynqmp-firmware/soc-nvmem/nvmem-layout/efuse-ppk0hash@a0";
		efuse_ppk1hash = "/firmware/zynqmp-firmware/soc-nvmem/nvmem-layout/efuse-ppk1hash@d0";
		efuse_pufuser = "/firmware/zynqmp-firmware/soc-nvmem/nvmem-layout/efuse-pufuser@100";
		zynqmp_pcap = "/firmware/zynqmp-firmware/pcap";
		zynqmp_reset = "/firmware/zynqmp-firmware/reset-controller";
		pinctrl0 = "/firmware/zynqmp-firmware/pinctrl";
		pinctrl_i2c0_default = "/firmware/zynqmp-firmware/pinctrl/i2c0-default";
		pinctrl_i2c0_gpio = "/firmware/zynqmp-firmware/pinctrl/i2c0-gpio-grp";
		pinctrl_i2c1_default = "/firmware/zynqmp-firmware/pinctrl/i2c1-default";
		pinctrl_i2c1_gpio = "/firmware/zynqmp-firmware/pinctrl/i2c1-gpio-grp";
		pinctrl_uart0_default = "/firmware/zynqmp-firmware/pinctrl/uart0-default";
		pinctrl_uart1_default = "/firmware/zynqmp-firmware/pinctrl/uart1-default";
		pinctrl_usb0_default = "/firmware/zynqmp-firmware/pinctrl/usb0-default";
		pinctrl_gem3_default = "/firmware/zynqmp-firmware/pinctrl/gem3-default";
		pinctrl_can1_default = "/firmware/zynqmp-firmware/pinctrl/can1-default";
		pinctrl_sdhci1_default = "/firmware/zynqmp-firmware/pinctrl/sdhci1-default";
		pinctrl_gpio_default = "/firmware/zynqmp-firmware/pinctrl/gpio-default";
		modepin_gpio = "/firmware/zynqmp-firmware/gpio";
		zynqmp_clk = "/firmware/zynqmp-firmware/clock-controller";
		fpga_full = "/fpga-region";
		amba_apu = "/apu-bus";
		amba = "/axi";
		imux = "/axi/interrupt-multiplex";
		can0 = "/axi/can@ff060000";
		can1 = "/axi/can@ff070000";
		cci = "/axi/cci@fd6e0000";
		fpd_dma_chan1 = "/axi/dma-controller@fd500000";
		fpd_dma_chan2 = "/axi/dma-controller@fd510000";
		fpd_dma_chan3 = "/axi/dma-controller@fd520000";
		fpd_dma_chan4 = "/axi/dma-controller@fd530000";
		fpd_dma_chan5 = "/axi/dma-controller@fd540000";
		fpd_dma_chan6 = "/axi/dma-controller@fd550000";
		fpd_dma_chan7 = "/axi/dma-controller@fd560000";
		fpd_dma_chan8 = "/axi/dma-controller@fd570000";
		gpu = "/axi/gpu@fd4b0000";
		lpd_dma_chan1 = "/axi/dma-controller@ffa80000";
		lpd_dma_chan2 = "/axi/dma-controller@ffa90000";
		lpd_dma_chan3 = "/axi/dma-controller@ffaa0000";
		lpd_dma_chan4 = "/axi/dma-controller@ffab0000";
		lpd_dma_chan5 = "/axi/dma-controller@ffac0000";
		lpd_dma_chan6 = "/axi/dma-controller@ffad0000";
		lpd_dma_chan7 = "/axi/dma-controller@ffae0000";
		lpd_dma_chan8 = "/axi/dma-controller@ffaf0000";
		mc = "/axi/memory-controller@fd070000";
		nand0 = "/axi/nand-controller@ff100000";
		gem0 = "/axi/ethernet@ff0b0000";
		gem1 = "/axi/ethernet@ff0c0000";
		gem2 = "/axi/ethernet@ff0d0000";
		gem3 = "/axi/ethernet@ff0e0000";
		mdio = "/axi/ethernet@ff0e0000/mdio";
		phyc = "/axi/ethernet@ff0e0000/mdio/ethernet-phy@c";
		gpio = "/axi/gpio@ff0a0000";
		i2c0 = "/axi/i2c@ff020000";
		tca6416_u97 = "/axi/i2c@ff020000/gpio@20";
		tca6416_u61 = "/axi/i2c@ff020000/gpio@21";
		u76 = "/axi/i2c@ff020000/i2c-mux@75/i2c@0/ina226@40";
		u77 = "/axi/i2c@ff020000/i2c-mux@75/i2c@0/ina226@41";
		u78 = "/axi/i2c@ff020000/i2c-mux@75/i2c@0/ina226@42";
		u87 = "/axi/i2c@ff020000/i2c-mux@75/i2c@0/ina226@43";
		u85 = "/axi/i2c@ff020000/i2c-mux@75/i2c@0/ina226@44";
		u86 = "/axi/i2c@ff020000/i2c-mux@75/i2c@0/ina226@45";
		u93 = "/axi/i2c@ff020000/i2c-mux@75/i2c@0/ina226@46";
		u88 = "/axi/i2c@ff020000/i2c-mux@75/i2c@0/ina226@47";
		u15 = "/axi/i2c@ff020000/i2c-mux@75/i2c@0/ina226@4a";
		u92 = "/axi/i2c@ff020000/i2c-mux@75/i2c@0/ina226@4b";
		u79 = "/axi/i2c@ff020000/i2c-mux@75/i2c@1/ina226@40";
		u81 = "/axi/i2c@ff020000/i2c-mux@75/i2c@1/ina226@41";
		u80 = "/axi/i2c@ff020000/i2c-mux@75/i2c@1/ina226@42";
		u84 = "/axi/i2c@ff020000/i2c-mux@75/i2c@1/ina226@43";
		u16 = "/axi/i2c@ff020000/i2c-mux@75/i2c@1/ina226@44";
		u65 = "/axi/i2c@ff020000/i2c-mux@75/i2c@1/ina226@45";
		u74 = "/axi/i2c@ff020000/i2c-mux@75/i2c@1/ina226@46";
		u75 = "/axi/i2c@ff020000/i2c-mux@75/i2c@1/ina226@47";
		i2c1 = "/axi/i2c@ff030000";
		eeprom = "/axi/i2c@ff030000/i2c-mux@74/i2c@0/eeprom@54";
		board_sn = "/axi/i2c@ff030000/i2c-mux@74/i2c@0/eeprom@54/board-sn@0";
		eth_mac = "/axi/i2c@ff030000/i2c-mux@74/i2c@0/eeprom@54/eth-mac@20";
		board_name = "/axi/i2c@ff030000/i2c-mux@74/i2c@0/eeprom@54/board-name@d0";
		board_revision = "/axi/i2c@ff030000/i2c-mux@74/i2c@0/eeprom@54/board-revision@e0";
		si5341 = "/axi/i2c@ff030000/i2c-mux@74/i2c@1/clock-generator@36";
		si5341_0 = "/axi/i2c@ff030000/i2c-mux@74/i2c@1/clock-generator@36/out@0";
		si5341_2 = "/axi/i2c@ff030000/i2c-mux@74/i2c@1/clock-generator@36/out@2";
		si5341_3 = "/axi/i2c@ff030000/i2c-mux@74/i2c@1/clock-generator@36/out@3";
		si5341_4 = "/axi/i2c@ff030000/i2c-mux@74/i2c@1/clock-generator@36/out@4";
		si5341_5 = "/axi/i2c@ff030000/i2c-mux@74/i2c@1/clock-generator@36/out@5";
		si5341_6 = "/axi/i2c@ff030000/i2c-mux@74/i2c@1/clock-generator@36/out@6";
		si5341_7 = "/axi/i2c@ff030000/i2c-mux@74/i2c@1/clock-generator@36/out@7";
		si5341_9 = "/axi/i2c@ff030000/i2c-mux@74/i2c@1/clock-generator@36/out@9";
		si570_1 = "/axi/i2c@ff030000/i2c-mux@74/i2c@2/clock-generator@5d";
		si570_2 = "/axi/i2c@ff030000/i2c-mux@74/i2c@3/clock-generator@5d";
		si5328 = "/axi/i2c@ff030000/i2c-mux@74/i2c@4/clock-generator@69";
		si5328_clk = "/axi/i2c@ff030000/i2c-mux@74/i2c@4/clock-generator@69/clk0@0";
		ocm = "/axi/memory-controller@ff960000";
		perf_monitor_ocm = "/axi/perf-monitor@ffa00000";
		perf_monitor_ddr = "/axi/perf-monitor@fd0b0000";
		perf_monitor_cci = "/axi/perf-monitor@fd490000";
		perf_monitor_lpd = "/axi/perf-monitor@ffa10000";
		pcie = "/axi/pcie@fd0e0000";
		pcie_intc = "/axi/pcie@fd0e0000/legacy-interrupt-controller";
		qspi = "/axi/spi@ff0f0000";
		psgtr = "/axi/phy@fd400000";
		rtc = "/axi/rtc@ffa60000";
		sata = "/axi/ahci@fd0c0000";
		sdhci0 = "/axi/mmc@ff160000";
		sdhci1 = "/axi/mmc@ff170000";
		smmu = "/axi/iommu@fd800000";
		spi0 = "/axi/spi@ff040000";
		spi1 = "/axi/spi@ff050000";
		ttc0 = "/axi/timer@ff110000";
		ttc1 = "/axi/timer@ff120000";
		ttc2 = "/axi/timer@ff130000";
		ttc3 = "/axi/timer@ff140000";
		uart0 = "/axi/serial@ff000000";
		uart1 = "/axi/serial@ff010000";
		usb0 = "/axi/usb@ff9d0000";
		dwc3_0 = "/axi/usb@ff9d0000/usb@fe200000";
		usb1 = "/axi/usb@ff9e0000";
		dwc3_1 = "/axi/usb@ff9e0000/usb@fe300000";
		watchdog0 = "/axi/watchdog@fd4d0000";
		lpd_watchdog = "/axi/watchdog@ff150000";
		xilinx_ams = "/axi/ams@ffa50000";
		ams_ps = "/axi/ams@ffa50000/ams-ps@0";
		ams_pl = "/axi/ams@ffa50000/ams-pl@400";
		zynqmp_dpdma = "/axi/dma-controller@fd4c0000";
		zynqmp_dpaud_setting = "/axi/dp-aud@fd4ac000";
		zynqmp_dpsub = "/axi/display@fd4a0000";
		zynqmp_dp_snd_codec0 = "/axi/display@fd4a0000/zynqmp-dp-snd-codec0";
		zynqmp_dp_snd_pcm0 = "/axi/display@fd4a0000/zynqmp-dp-snd-pcm0";
		zynqmp_dp_snd_pcm1 = "/axi/display@fd4a0000/zynqmp-dp-snd-pcm1";
		zynqmp_dp_snd_card0 = "/axi/display@fd4a0000/zynqmp-dp-snd-card";
		coresight_0 = "/axi/coresight@fe800000";
		csudma_0 = "/axi/dma@ffc80000";
		ipi9 = "/axi/ipi@ff360000";
		ipi10 = "/axi/ipi@ff370000";
		psu_csu_0 = "/axi/psu_csu@ffca0000";
		psu_smmu_reg = "/axi/psu_smmu_reg@fd5f0000";
		psu_cci_reg = "/axi/psu_cci_reg@fd5e0000";
		psu_afi_5 = "/axi/psu_afi@fd3b0000";
		psu_afi_4 = "/axi/psu_afi@fd3a0000";
		psu_afi_3 = "/axi/psu_afi@fd390000";
		psu_afi_2 = "/axi/psu_afi@fd380000";
		psu_afi_1 = "/axi/psu_afi@fd370000";
		psu_afi_0 = "/axi/psu_afi@fd360000";
		psu_pcie_low = "/axi/psu_pcie@e0000000";
		psu_pcie_high1 = "/axi/psu_pcie@600000000";
		psu_pcie_high2 = "/axi/psu_pcie@8000000000";
		psu_afi_6 = "/axi/psu_afi@ff9b0000";
		psu_ctrl_ipi = "/axi/PERIPHERAL@ff380000";
		psu_message_buffers = "/axi/PERIPHERAL@ff990000";
		psu_iouslcr_0 = "/axi/psu_iouslcr@ff180000";
		psu_qspi_linear_0 = "/axi/psu_qspi_linear@c0000000";
		amba_xppu = "/indirect-bus@1";
		lpd_xppu = "/indirect-bus@1/xppu@ff980000";
		pss_ref_clk = "/pss_ref_clk";
		video_clk = "/video_clk";
		pss_alt_ref_clk = "/pss_alt_ref_clk";
		gt_crx_ref_clk = "/gt_crx_ref_clk";
		aux_ref_clk = "/aux_ref_clk";
		amba_pl = "/amba_pl";
		misc_clk_0 = "/amba_pl/misc_clk_0";
		axi_intc_0 = "/amba_pl/interrupt-controller@80020000";
		psu_ddr_0_memory = "/memory@0";
		psu_ddr_1_memory = "/memory@800000000";
		ref48 = "/ref48M";
		refhdmi = "/refhdmi";
		gic = "/axi/interrupt-controller@f9010000";
		flash0 = "/axi/spi@ff0f0000/flash@0";
	};
};
